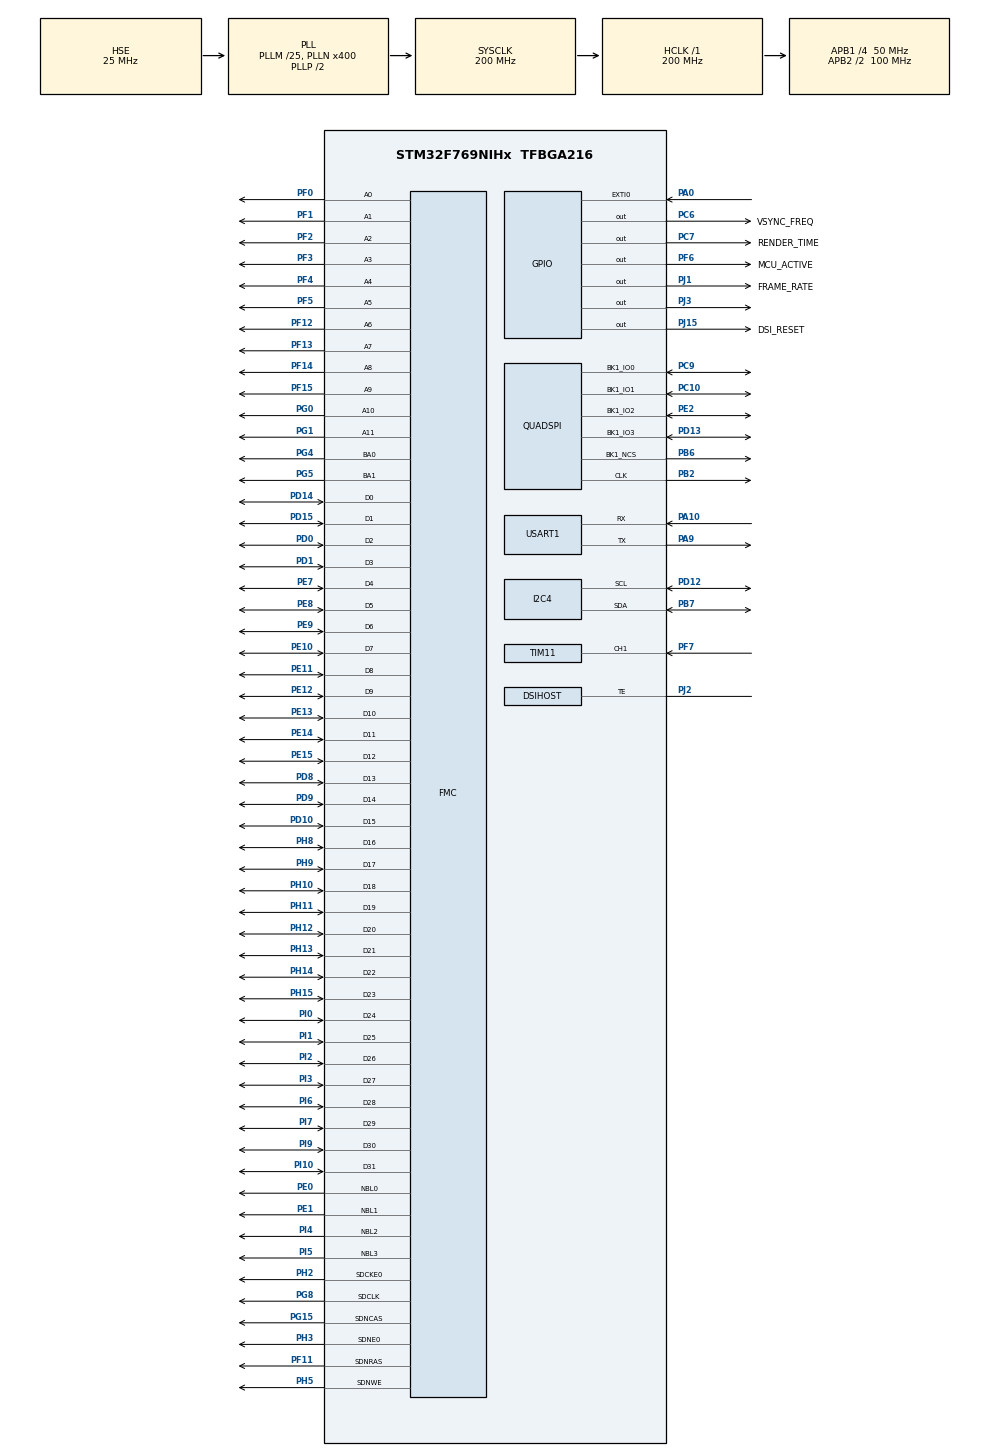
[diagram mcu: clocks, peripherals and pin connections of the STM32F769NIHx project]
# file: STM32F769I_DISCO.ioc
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CORTEX_M7.ART_ACCLERATOR_ENABLE=1
CORTEX_M7.AccessPermission-Cortex_Memory_Protection_Unit_Region0_Settings=MPU_REGION_FULL_ACCESS
CORTEX_M7.AccessPermission-Cortex_Memory_Protection_Unit_Region1_Settings=MPU_REGION_NO_ACCESS
CORTEX_M7.AccessPermission-Cortex_Memory_Protection_Unit_Region2_Settings=MPU_REGION_FULL_ACCESS
CORTEX_M7.AccessPermission-Cortex_Memory_Protection_Unit_Region3_Settings=MPU_REGION_NO_ACCESS
CORTEX_M7.AccessPermission-Cortex_Memory_Protection_Unit_Region4_Settings=MPU_REGION_FULL_ACCESS
CORTEX_M7.BaseAddress-Cortex_Memory_Protection_Unit_Region0_Settings=0x20000000
CORTEX_M7.BaseAddress-Cortex_Memory_Protection_Unit_Region1_Settings=0x90000000
CORTEX_M7.BaseAddress-Cortex_Memory_Protection_Unit_Region2_Settings=0x90000000
CORTEX_M7.BaseAddress-Cortex_Memory_Protection_Unit_Region3_Settings=0xC0000000
CORTEX_M7.BaseAddress-Cortex_Memory_Protection_Unit_Region4_Settings=0xC0000000
CORTEX_M7.CPU_DCache=Enabled
CORTEX_M7.CPU_ICache=Enabled
CORTEX_M7.DisableExec-Cortex_Memory_Protection_Unit_Region0_Settings=MPU_INSTRUCTION_ACCESS_DISABLE
CORTEX_M7.DisableExec-Cortex_Memory_Protection_Unit_Region1_Settings=MPU_INSTRUCTION_ACCESS_DISABLE
CORTEX_M7.DisableExec-Cortex_Memory_Protection_Unit_Region2_Settings=MPU_INSTRUCTION_ACCESS_DISABLE
CORTEX_M7.DisableExec-Cortex_Memory_Protection_Unit_Region3_Settings=MPU_INSTRUCTION_ACCESS_DISABLE
CORTEX_M7.DisableExec-Cortex_Memory_Protection_Unit_Region4_Settings=MPU_INSTRUCTION_ACCESS_DISABLE
CORTEX_M7.Enable-Cortex_Memory_Protection_Unit_Region0_Settings=MPU_REGION_ENABLE
CORTEX_M7.Enable-Cortex_Memory_Protection_Unit_Region1_Settings=MPU_REGION_ENABLE
CORTEX_M7.Enable-Cortex_Memory_Protection_Unit_Region2_Settings=MPU_REGION_ENABLE
CORTEX_M7.Enable-Cortex_Memory_Protection_Unit_Region3_Settings=MPU_REGION_ENABLE
CORTEX_M7.Enable-Cortex_Memory_Protection_Unit_Region4_Settings=MPU_REGION_ENABLE
CORTEX_M7.IsBufferable-Cortex_Memory_Protection_Unit_Region0_Settings=MPU_ACCESS_BUFFERABLE
CORTEX_M7.IsBufferable-Cortex_Memory_Protection_Unit_Region2_Settings=MPU_ACCESS_BUFFERABLE
CORTEX_M7.IsBufferable-Cortex_Memory_Protection_Unit_Region3_Settings=MPU_ACCESS_NOT_BUFFERABLE
CORTEX_M7.IsBufferable-Cortex_Memory_Protection_Unit_Region4_Settings=MPU_ACCESS_BUFFERABLE
CORTEX_M7.IsCacheable-Cortex_Memory_Protection_Unit_Region0_Settings=MPU_ACCESS_CACHEABLE
CORTEX_M7.IsCacheable-Cortex_Memory_Protection_Unit_Region2_Settings=MPU_ACCESS_CACHEABLE
CORTEX_M7.IsCacheable-Cortex_Memory_Protection_Unit_Region3_Settings=MPU_ACCESS_NOT_CACHEABLE
CORTEX_M7.IsCacheable-Cortex_Memory_Protection_Unit_Region4_Settings=MPU_ACCESS_CACHEABLE
CORTEX_M7.IsShareable-Cortex_Memory_Protection_Unit_Region0_Settings=MPU_ACCESS_NOT_SHAREABLE
CORTEX_M7.IsShareable-Cortex_Memory_Protection_Unit_Region2_Settings=MPU_ACCESS_NOT_SHAREABLE
CORTEX_M7.MPU_Control=MPU_PRIVILEGED_DEFAULT
CORTEX_M7.PREFETCH_ENABLE=1
CORTEX_M7.Size-Cortex_Memory_Protection_Unit_Region0_Settings=MPU_REGION_SIZE_512KB
CORTEX_M7.Size-Cortex_Memory_Protection_Unit_Region1_Settings=MPU_REGION_SIZE_512MB
CORTEX_M7.Size-Cortex_Memory_Protection_Unit_Region2_Settings=MPU_REGION_SIZE_64MB
CORTEX_M7.Size-Cortex_Memory_Protection_Unit_Region3_Settings=MPU_REGION_SIZE_512MB
CORTEX_M7.Size-Cortex_Memory_Protection_Unit_Region4_Settings=MPU_REGION_SIZE_16MB
DMA2D.ColorMode=DMA2D_OUTPUT_ARGB8888
DMA2D.Mode=DMA2D_M2M
DSIHOST.AcknowledgeRequest=DSI_ACKNOWLEDGE_ENABLE
DSIHOST.AutomaticRefresh=DSI_AR_DISABLE
DSIHOST.BTA_FlowControl=DSI_FLOW_CONTROL_BTA
DSIHOST.CommandSize=200
DSIHOST.LPDcsLongWrite=DSI_LP_DLW_ENABLE
DSIHOST.LPDcsShortReadNoP=DSI_LP_DSR0P_ENABLE
DSIHOST.LPDcsShortWriteNoP=DSI_LP_DSW0P_ENABLE
DSIHOST.LPDcsShortWriteOneP=DSI_LP_DSW1P_ENABLE
DSIHOST.LPGenLongWrite=DSI_LP_GLW_ENABLE
DSIHOST.LPGenShortReadNoP=DSI_LP_GSR0P_ENABLE
DSIHOST.LPGenShortReadOneP=DSI_LP_GSR1P_ENABLE
DSIHOST.LPGenShortReadTwoP=DSI_LP_GSR2P_ENABLE
DSIHOST.LPGenShortWriteNoP=DSI_LP_GSW0P_ENABLE
DSIHOST.LPGenShortWriteOneP=DSI_LP_GSW1P_ENABLE
DSIHOST.LPGenShortWriteTwoP=DSI_LP_GSW2P_ENABLE
DSIHOST.LPMaxReadPacket=DSI_LP_MRDP_ENABLE
DSIHOST.LPWREIE=HAL_DSI_ERROR_OVF
DSIHOST.NumberOfLanes=DSI_TWO_DATA_LANES
DSIHOST.TEAcknowledgeRequest=DSI_TE_ACKNOWLEDGE_ENABLE
DSIHOST_CKN.Mode=DSIHost_Adapted_TE
DSIHOST_CKN.Signal=DSIHOST_CKN
DSIHOST_CKP.Mode=DSIHost_Adapted_TE
DSIHOST_CKP.Signal=DSIHOST_CKP
DSIHOST_D0N.Mode=DSIHost_Adapted_TE
DSIHOST_D0N.Signal=DSIHOST_D0N
DSIHOST_D0P.Mode=DSIHost_Adapted_TE
DSIHOST_D0P.Signal=DSIHOST_D0P
DSIHOST_D1N.Mode=DSIHost_Adapted_TE
DSIHOST_D1N.Signal=DSIHOST_D1N
DSIHOST_D1P.Mode=DSIHost_Adapted_TE
DSIHOST_D1P.Signal=DSIHOST_D1P
Dma.JPEG_IN.0.Direction=DMA_MEMORY_TO_PERIPH
Dma.JPEG_IN.0.FIFOMode=DMA_FIFOMODE_ENABLE
Dma.JPEG_IN.0.FIFOThreshold=DMA_FIFO_THRESHOLD_FULL
Dma.JPEG_IN.0.Instance=DMA2_Stream0
Dma.JPEG_IN.0.MemBurst=DMA_MBURST_INC4
Dma.JPEG_IN.0.MemDataAlignment=DMA_MDATAALIGN_WORD
Dma.JPEG_IN.0.MemInc=DMA_MINC_ENABLE
Dma.JPEG_IN.0.Mode=DMA_NORMAL
Dma.JPEG_IN.0.PeriphBurst=DMA_PBURST_INC4
Dma.JPEG_IN.0.PeriphDataAlignment=DMA_PDATAALIGN_WORD
Dma.JPEG_IN.0.PeriphInc=DMA_PINC_DISABLE
Dma.JPEG_IN.0.Priority=DMA_PRIORITY_LOW
Dma.JPEG_OUT.1.Direction=DMA_PERIPH_TO_MEMORY
Dma.JPEG_OUT.1.FIFOMode=DMA_FIFOMODE_ENABLE
Dma.JPEG_OUT.1.FIFOThreshold=DMA_FIFO_THRESHOLD_FULL
Dma.JPEG_OUT.1.Instance=DMA2_Stream1
Dma.JPEG_OUT.1.MemBurst=DMA_MBURST_INC4
Dma.JPEG_OUT.1.MemDataAlignment=DMA_MDATAALIGN_WORD
Dma.JPEG_OUT.1.MemInc=DMA_MINC_ENABLE
Dma.JPEG_OUT.1.Mode=DMA_NORMAL
Dma.JPEG_OUT.1.PeriphBurst=DMA_PBURST_INC4
Dma.JPEG_OUT.1.PeriphDataAlignment=DMA_PDATAALIGN_WORD
Dma.JPEG_OUT.1.PeriphInc=DMA_PINC_DISABLE
Dma.JPEG_OUT.1.Priority=DMA_PRIORITY_LOW
Dma.Request0=JPEG_IN
Dma.Request1=JPEG_OUT
FMC.CASLatency1=FMC_SDRAM_CAS_LATENCY_3
FMC.ExitSelfRefreshDelay1=7
FMC.LoadToActiveDelay1=2
FMC.RCDDelay1=3
FMC.RPDelay1=2
FMC.ReadBurst1=FMC_SDRAM_RBURST_ENABLE
FMC.RowCycleDelay1=7
FMC.SDClockPeriod1=FMC_SDRAM_CLOCK_PERIOD_2
FMC.SelfRefreshTime1=4
FMC.WriteRecoveryTime1=2
FREERTOS.Tasks01=defaultTask,24,128,StartDefaultTask,Default,NULL,Dynamic,NULL,NULL;TouchGFXTask,24,4096,TouchGFX_Task,As external,NULL,Dynamic,NULL,NULL;videoTask,8,1000,videoTaskFunc,As external,NULL,Dynamic,NULL,NULL
FREERTOS.configTOTAL_HEAP_SIZE=80000
FREERTOS.configUSE_IDLE_HOOK=1
FREERTOS.configUSE_NEWLIB_REENTRANT=1
I2C4.Timing=0x00C0EAFF
JPEG.JPEG_RGB_FORMAT=JPEG_RGB565
LIBJPEG.RGB_ORDERING=BGR
LTDC.ActiveH=480
LTDC.ActiveW=200
LTDC.Alpha_L0=255
LTDC.BlendingFactor1_L0=LTDC_BLENDING_FACTOR1_CA
LTDC.BlendingFactor2_L0=LTDC_BLENDING_FACTOR2_CA
LTDC.FBStartAdress_L0=0xC0000000
LTDC.HBP=1
LTDC.HFP=1
LTDC.HSync=2
LTDC.ImageHeight_L0=480
LTDC.ImageWidth_L0=200
LTDC.Layers=0
LTDC.PixelFormat_L0=LTDC_PIXEL_FORMAT_RGB565
LTDC.Red=0
LTDC.VBP=1
LTDC.VFP=1
LTDC.VSync=2
LTDC.WindowX1_L0=200
LTDC.WindowY1_L0=480
Mcu.Family=STM32F7
Mcu.Name=STM32F769NIHx
Mcu.Package=TFBGA216
NVIC.DMA2D_IRQn=true\:5\:0\:false\:false\:true\:true\:true\:true\:true
NVIC.DMA2_Stream0_IRQn=true\:5\:0\:false\:false\:true\:true\:false\:true\:true
NVIC.DMA2_Stream1_IRQn=true\:5\:0\:false\:false\:true\:true\:false\:true\:true
NVIC.DSI_IRQn=true\:5\:0\:false\:false\:true\:true\:true\:true\:true
NVIC.EXTI0_IRQn=true\:5\:0\:false\:false\:true\:true\:true\:true\:true
NVIC.I2C4_EV_IRQn=true\:5\:0\:false\:false\:true\:false\:true\:true\:true
NVIC.JPEG_IRQn=true\:5\:0\:false\:false\:true\:true\:false\:true\:true
NVIC.LTDC_IRQn=true\:3\:0\:true\:false\:true\:false\:true\:true\:true
NVIC.PriorityGroup=NVIC_PRIORITYGROUP_4
NVIC.TIM1_TRG_COM_TIM11_IRQn=true\:5\:0\:false\:false\:true\:true\:true\:true\:true
NVIC.TIM6_DAC_IRQn=true\:0\:0\:false\:false\:true\:false\:false\:true\:true
NVIC.TimeBase=TIM6_DAC_IRQn
NVIC.TimeBaseIP=TIM6
NVIC.USART1_IRQn=true\:5\:0\:false\:false\:true\:true\:true\:true\:true
PA0/WKUP.Signal=GPXTI0
PA10.Mode=Asynchronous
PA10.Signal=USART1_RX
PA9.Mode=Asynchronous
PA9.Signal=USART1_TX
PB2.Mode=Single Bank 1
PB2.Signal=QUADSPI_CLK
PB6.GPIO_PuPd=GPIO_PULLUP
PB6.Mode=Single Bank 1
PB6.Signal=QUADSPI_BK1_NCS
PB7.GPIO_Pu=GPIO_PULLUP
PB7.Mode=I2C
PB7.Signal=I2C4_SDA
PC10.Mode=Single Bank 1
PC10.Signal=QUADSPI_BK1_IO1
PC6.GPIO_Label=VSYNC_FREQ
PC6.GPIO_Speed=GPIO_SPEED_FREQ_VERY_HIGH
PC6.Signal=GPIO_Output
PC7.GPIO_Label=RENDER_TIME
PC7.GPIO_Speed=GPIO_SPEED_FREQ_VERY_HIGH
PC7.Signal=GPIO_Output
PC9.Mode=Single Bank 1
PC9.Signal=QUADSPI_BK1_IO0
PD0.Signal=FMC_D2_DA2
PD1.Signal=FMC_D3_DA3
PD10.Signal=FMC_D15_DA15
PD12.GPIO_Pu=GPIO_PULLUP
PD12.Mode=I2C
PD12.Signal=I2C4_SCL
PD13.Mode=Single Bank 1
PD13.Signal=QUADSPI_BK1_IO3
PD14.Signal=FMC_D0_DA0
PD15.Signal=FMC_D1_DA1
PD8.Signal=FMC_D13_DA13
PD9.Signal=FMC_D14_DA14
PE0.Signal=FMC_NBL0
PE1.Signal=FMC_NBL1
PE10.Signal=FMC_D7_DA7
PE11.Signal=FMC_D8_DA8
PE12.Signal=FMC_D9_DA9
PE13.Signal=FMC_D10_DA10
PE14.Signal=FMC_D11_DA11
PE15.Signal=FMC_D12_DA12
PE2.Mode=Single Bank 1
PE2.Signal=QUADSPI_BK1_IO2
PE7.Signal=FMC_D4_DA4
PE8.Signal=FMC_D5_DA5
PE9.Signal=FMC_D6_DA6
PF0.Signal=FMC_A0
PF1.Signal=FMC_A1
PF11.Signal=FMC_SDNRAS
PF12.Signal=FMC_A6
PF13.Signal=FMC_A7
PF14.Signal=FMC_A8
PF15.Signal=FMC_A9
PF2.Signal=FMC_A2
PF3.Signal=FMC_A3
PF4.Signal=FMC_A4
PF5.Signal=FMC_A5
PF6.GPIO_Label=MCU_ACTIVE
PF6.GPIO_Speed=GPIO_SPEED_FREQ_VERY_HIGH
PF6.Signal=GPIO_Output
PF7.Signal=S_TIM11_CH1
PG0.Signal=FMC_A10
PG1.Signal=FMC_A11
PG15.Signal=FMC_SDNCAS
PG4.Signal=FMC_A14_BA0
PG5.Signal=FMC_A15_BA1
PG8.Signal=FMC_SDCLK
PH0/OSC_IN.Mode=HSE-External-Oscillator
PH0/OSC_IN.Signal=RCC_OSC_IN
PH1/OSC_OUT.Mode=HSE-External-Oscillator
PH1/OSC_OUT.Signal=RCC_OSC_OUT
PH10.Signal=FMC_D18
PH11.Signal=FMC_D19
PH12.Signal=FMC_D20
PH13.Signal=FMC_D21
PH14.Signal=FMC_D22
PH15.Signal=FMC_D23
PH2.Mode=SdramChipSelect1_1
PH2.Signal=FMC_SDCKE0
PH3.Mode=SdramChipSelect1_1
PH3.Signal=FMC_SDNE0
PH5.Signal=FMC_SDNWE
PH8.Signal=FMC_D16
PH9.Signal=FMC_D17
PI0.Signal=FMC_D24
PI1.Signal=FMC_D25
PI10.Signal=FMC_D31
PI2.Signal=FMC_D26
PI3.Signal=FMC_D27
PI4.Signal=FMC_NBL2
PI5.Signal=FMC_NBL3
PI6.Signal=FMC_D28
PI7.Signal=FMC_D29
PI9.Signal=FMC_D30
PJ1.GPIO_Label=FRAME_RATE
PJ1.GPIO_Speed=GPIO_SPEED_FREQ_VERY_HIGH
PJ1.Signal=GPIO_Output
PJ15.GPIO_Label=DSI_RESET
PJ15.GPIO_PuPd=GPIO_PULLUP
PJ15.GPIO_Speed=GPIO_SPEED_FREQ_MEDIUM
PJ15.PinState=GPIO_PIN_SET
PJ15.Signal=GPIO_Output
PJ2.Mode=DSIHost_Adapted_TE
PJ2.Signal=DSIHOST_TE
PJ3.Signal=GPIO_Output
ProjectManager.HeapSize=0x1000
ProjectManager.StackSize=0x1000
ProjectManager.TargetToolchain=STM32CubeIDE
QUADSPI.ChipSelectHighTime=QSPI_CS_HIGH_TIME_4_CYCLE
QUADSPI.ClockPrescaler=1
QUADSPI.FifoThreshold=16
QUADSPI.FlashSize=25
QUADSPI.SampleShifting=QSPI_SAMPLE_SHIFTING_HALFCYCLE
RCC.AHBFreq_Value=200000000
RCC.APB1CLKDivider=RCC_HCLK_DIV4
RCC.APB1Freq_Value=50000000
RCC.APB1TimFreq_Value=100000000
RCC.APB2CLKDivider=RCC_HCLK_DIV2
RCC.APB2Freq_Value=100000000
RCC.APB2TimFreq_Value=200000000
RCC.CortexFreq_Value=200000000
RCC.HCLKFreq_Value=200000000
RCC.HSE_VALUE=25000000
RCC.HSI_VALUE=16000000
RCC.LSE_VALUE=32768
RCC.PLLDSIIDF=DSI_PLL_IN_DIV5
RCC.PLLDSINDIV=100
RCC.PLLM=25
RCC.PLLN=400
RCC.PLLR=7
RCC.PLLSAIN=384
RCC.PLLSAIR=7
RCC.PLLSourceVirtual=RCC_PLLSOURCE_HSE
RCC.SYSCLKFreq_VALUE=200000000
RCC.SYSCLKSource=RCC_SYSCLKSOURCE_PLLCLK
RCC.USBFreq_Value=200000000
RCC.VCOOutputFreq_Value=400000000
SH.FMC_A0.0=FMC_A0,12b-sda1
SH.FMC_A1.0=FMC_A1,12b-sda1
SH.FMC_A10.0=FMC_A10,12b-sda1
SH.FMC_A11.0=FMC_A11,12b-sda1
SH.FMC_A14_BA0.0=FMC_BA0,FourSdramBanks1
SH.FMC_A15_BA1.0=FMC_BA1,FourSdramBanks1
SH.FMC_A2.0=FMC_A2,12b-sda1
SH.FMC_A3.0=FMC_A3,12b-sda1
SH.FMC_A4.0=FMC_A4,12b-sda1
SH.FMC_A5.0=FMC_A5,12b-sda1
SH.FMC_A6.0=FMC_A6,12b-sda1
SH.FMC_A7.0=FMC_A7,12b-sda1
SH.FMC_A8.0=FMC_A8,12b-sda1
SH.FMC_A9.0=FMC_A9,12b-sda1
SH.FMC_D0_DA0.0=FMC_D0,sd-32b-d1
SH.FMC_D10_DA10.0=FMC_D10,sd-32b-d1
SH.FMC_D11_DA11.0=FMC_D11,sd-32b-d1
SH.FMC_D12_DA12.0=FMC_D12,sd-32b-d1
SH.FMC_D13_DA13.0=FMC_D13,sd-32b-d1
SH.FMC_D14_DA14.0=FMC_D14,sd-32b-d1
SH.FMC_D15_DA15.0=FMC_D15,sd-32b-d1
SH.FMC_D16.0=FMC_D16,sd-32b-d1
SH.FMC_D17.0=FMC_D17,sd-32b-d1
SH.FMC_D18.0=FMC_D18,sd-32b-d1
SH.FMC_D19.0=FMC_D19,sd-32b-d1
SH.FMC_D1_DA1.0=FMC_D1,sd-32b-d1
SH.FMC_D20.0=FMC_D20,sd-32b-d1
SH.FMC_D21.0=FMC_D21,sd-32b-d1
SH.FMC_D22.0=FMC_D22,sd-32b-d1
SH.FMC_D23.0=FMC_D23,sd-32b-d1
SH.FMC_D24.0=FMC_D24,sd-32b-d1
SH.FMC_D25.0=FMC_D25,sd-32b-d1
SH.FMC_D26.0=FMC_D26,sd-32b-d1
SH.FMC_D27.0=FMC_D27,sd-32b-d1
SH.FMC_D28.0=FMC_D28,sd-32b-d1
SH.FMC_D29.0=FMC_D29,sd-32b-d1
SH.FMC_D2_DA2.0=FMC_D2,sd-32b-d1
SH.FMC_D30.0=FMC_D30,sd-32b-d1
SH.FMC_D31.0=FMC_D31,sd-32b-d1
SH.FMC_D3_DA3.0=FMC_D3,sd-32b-d1
SH.FMC_D4_DA4.0=FMC_D4,sd-32b-d1
SH.FMC_D5_DA5.0=FMC_D5,sd-32b-d1
SH.FMC_D6_DA6.0=FMC_D6,sd-32b-d1
SH.FMC_D7_DA7.0=FMC_D7,sd-32b-d1
SH.FMC_D8_DA8.0=FMC_D8,sd-32b-d1
SH.FMC_D9_DA9.0=FMC_D9,sd-32b-d1
SH.FMC_NBL0.0=FMC_NBL0,Sd4ByteEnable1
SH.FMC_NBL1.0=FMC_NBL1,Sd4ByteEnable1
SH.FMC_NBL2.0=FMC_NBL2,Sd4ByteEnable1
SH.FMC_NBL3.0=FMC_NBL3,Sd4ByteEnable1
SH.FMC_SDCLK.0=FMC_SDCLK,12b-sda1
SH.FMC_SDNCAS.0=FMC_SDNCAS,12b-sda1
SH.FMC_SDNRAS.0=FMC_SDNRAS,12b-sda1
SH.FMC_SDNWE.0=FMC_SDNWE,12b-sda1
SH.S_TIM11_CH1.0=TIM11_CH1,Input_Capture1_from_TI1
STMicroelectronics.X-CUBE-TOUCHGFX.4.22.1.ApplicationCcGraphicsJjApplication=TouchGFXOoGenerator
STMicroelectronics.X-CUBE-TOUCHGFX.4.22.1.tgfx_address1=0xC0000000
STMicroelectronics.X-CUBE-TOUCHGFX.4.22.1.tgfx_address2=0xC011A000
STMicroelectronics.X-CUBE-TOUCHGFX.4.22.1.tgfx_buffering_strategy=Single
STMicroelectronics.X-CUBE-TOUCHGFX.4.22.1.tgfx_custom_height=480
STMicroelectronics.X-CUBE-TOUCHGFX.4.22.1.tgfx_custom_width=800
STMicroelectronics.X-CUBE-TOUCHGFX.4.22.1.tgfx_hardware_accelerator=dma_2d
STMicroelectronics.X-CUBE-TOUCHGFX.4.22.1.tgfx_location=Allocate
STMicroelectronics.X-CUBE-TOUCHGFX.4.22.1.tgfx_pixel_format=RGB565\:16
STMicroelectronics.X-CUBE-TOUCHGFX.4.22.1.tgfx_vector_rendering=Enabled
STMicroelectronics.X-CUBE-TOUCHGFX.4.22.1.tgfx_video=Hardware
STMicroelectronics.X-CUBE-TOUCHGFX.4.22.1.tgfx_video_height=480
STMicroelectronics.X-CUBE-TOUCHGFX.4.22.1.tgfx_video_strategy=1
STMicroelectronics.X-CUBE-TOUCHGFX.4.22.1.tgfx_video_width=800
TIM11.Channel=TIM_CHANNEL_1
TIM11.Period=0xffff-1
TIM11.Prescaler=95
USART1.VirtualMode-Asynchronous=VM_ASYNC
VP_CRC_VS_CRC.Mode=CRC_Activate
VP_DMA2D_VS_DMA2D.Mode=DMA2D_Activate
VP_FREERTOS_VS_CMSIS_V2.Mode=CMSIS_V2
VP_JPEG_VS_JPEG.Mode=JPEG_Activate
VP_LIBJPEG_VS_JPEGLIB.Mode=Enabled
VP_LTDC_DSIMode.Mode=RGB565
VP_STMicroelectronics.X-CUBE-TOUCHGFX_VS_GraphicsJjApplication_4.22.1.Mode=GraphicsJjApplication
VP_SYS_VS_tim6.Mode=TIM6
VP_TIM11_VS_ClockSourceINT.Mode=Enable_Timer
board=custom

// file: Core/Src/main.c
/* USER CODE BEGIN Header */
/**
  ******************************************************************************
  * @file           : main.c
  * @brief          : Main program body
  ******************************************************************************
  * @attention
  *
  * <h2><center>&copy; Copyright (c) 2020 STMicroelectronics.
  * All rights reserved.</center></h2>
  *
  * This software component is licensed by ST under BSD 3-Clause license,
  * the "License"; You may not use this file except in compliance with the
  * License. You may obtain a copy of the License at:
  *                        opensource.org/licenses/BSD-3-Clause
  *
  ******************************************************************************
  */
/* USER CODE END Header */
#include "main.h"
#include "cmsis_os.h"
#include "libjpeg.h"
#include "app_touchgfx.h"
/* USER CODE BEGIN Includes */
#include "../mx25l512/mx25l512.h"
#include "../otm8009a/otm8009a.h"
/* USER CODE END Includes */

/* USER CODE BEGIN PD */

#define REFRESH_COUNT        1834
#define SDRAM_TIMEOUT                            ((uint32_t)0xFFFF)
#define SDRAM_MODEREG_BURST_LENGTH_1             ((uint16_t)0x0000)
#define SDRAM_MODEREG_BURST_LENGTH_2             ((uint16_t)0x0001)
#define SDRAM_MODEREG_BURST_LENGTH_4             ((uint16_t)0x0002)
#define SDRAM_MODEREG_BURST_LENGTH_8             ((uint16_t)0x0004)
#define SDRAM_MODEREG_BURST_TYPE_SEQUENTIAL      ((uint16_t)0x0000)
#define SDRAM_MODEREG_BURST_TYPE_INTERLEAVED     ((uint16_t)0x0008)
#define SDRAM_MODEREG_CAS_LATENCY_2              ((uint16_t)0x0020)
#define SDRAM_MODEREG_CAS_LATENCY_3              ((uint16_t)0x0030)
#define SDRAM_MODEREG_OPERATING_MODE_STANDARD    ((uint16_t)0x0000)
#define SDRAM_MODEREG_WRITEBURST_MODE_PROGRAMMED ((uint16_t)0x0000)
#define SDRAM_MODEREG_WRITEBURST_MODE_SINGLE     ((uint16_t)0x0200)

/* QSPI Error codes */
#define QSPI_OK            ((uint8_t)0x00)
#define QSPI_ERROR         ((uint8_t)0x01)
#define QSPI_BUSY          ((uint8_t)0x02)
#define QSPI_NOT_SUPPORTED ((uint8_t)0x04)
#define QSPI_SUSPENDED     ((uint8_t)0x08)

/* DISPLAY */
#define LCD_ORIENTATION_LANDSCAPE 0x01
/* USER CODE END PD */

CRC_HandleTypeDef hcrc;

DMA2D_HandleTypeDef hdma2d;

DSI_HandleTypeDef hdsi;

I2C_HandleTypeDef hi2c4;

JPEG_HandleTypeDef hjpeg;
DMA_HandleTypeDef hdma_jpeg_in;
DMA_HandleTypeDef hdma_jpeg_out;

LTDC_HandleTypeDef hltdc;

QSPI_HandleTypeDef hqspi;

TIM_HandleTypeDef htim11;

UART_HandleTypeDef huart1;

SDRAM_HandleTypeDef hsdram1;

/* Definitions for defaultTask */
osThreadId_t defaultTaskHandle;
const osThreadAttr_t defaultTask_attributes = {
  .name = "defaultTask",
  .stack_size = 128 * 4,
  .priority = (osPriority_t) osPriorityNormal,
};
/* Definitions for TouchGFXTask */
osThreadId_t TouchGFXTaskHandle;
const osThreadAttr_t TouchGFXTask_attributes = {
  .name = "TouchGFXTask",
  .stack_size = 4096 * 4,
  .priority = (osPriority_t) osPriorityNormal,
};
/* Definitions for videoTask */
osThreadId_t videoTaskHandle;
const osThreadAttr_t videoTask_attributes = {
  .name = "videoTask",
  .stack_size = 1000 * 4,
  .priority = (osPriority_t) osPriorityLow,
};

/* Definitions for defaultTask */
osThreadId_t sensorTaskHandle;
const osThreadAttr_t sensorTask_attributes = {
  .name = "sensorTask",
  .stack_size = 128 * 4,
  .priority = (osPriority_t) osPriorityNormal,
};
/* USER CODE BEGIN PV */
uint32_t IC_Val1 = 0;
uint32_t IC_Val2 = 0;
uint32_t Difference = 0;
uint8_t Is_First_Captured = 0;  // is the first value captured ?
uint8_t Distance  = 0;
uint8_t updateScreen = 0;
uint8_t serialNumber=0;
uint8_t distance[5]={0,0,0,0,0};

#define DHT22_PORT GPIOJ
#define DHT22_PIN  GPIO_PIN_1
uint8_t RH1, RH2, TC1, TC2, SUM, CHECK;
uint32_t pMillis, cMillis;
float tCelsius = 50;
float tFahrenheit = 0;
float RH = 0;
int a=5;

#define TRIG_PIN GPIO_PIN_3
#define TRIG_PORT GPIOJ
//#define TRIG_PIN_2 GPIO_PIN_1
/* USER CODE END PV */

void SystemClock_Config(void);
static void MPU_Initialize(void);
static void MPU_Config(void);
static void MX_GPIO_Init(void);
static void MX_DMA_Init(void);
static void MX_DSIHOST_DSI_Init(void);
static void MX_LTDC_Init(void);
static void MX_FMC_Init(void);
static void MX_QUADSPI_Init(void);
static void MX_DMA2D_Init(void);
static void MX_CRC_Init(void);
static void MX_JPEG_Init(void);
static void MX_TIM11_Init(void);
static void MX_USART1_UART_Init(void);
void StartDefaultTask(void *argument);
void sensorTaskFunc(void *argument);
extern void TouchGFX_Task(void *argument);
extern void videoTaskFunc(void *argument);

/* USER CODE BEGIN PFP */
static void BSP_SDRAM_Initialization_Sequence(SDRAM_HandleTypeDef *hsdram, FMC_SDRAM_CommandTypeDef *Command);

static uint8_t QSPI_ResetMemory(QSPI_HandleTypeDef *hqspi);
static uint8_t QSPI_EnterMemory_QPI(QSPI_HandleTypeDef *hqspi);
static uint8_t QSPI_EnterFourBytesAddress(QSPI_HandleTypeDef *hqspi);
static uint8_t QSPI_DummyCyclesCfg(QSPI_HandleTypeDef *hqspi);
static uint8_t QSPI_OutDrvStrengthCfg(QSPI_HandleTypeDef *hqspi);
static uint8_t QSPI_WriteEnable(QSPI_HandleTypeDef *hqspi);
static uint8_t QSPI_AutoPollingMemReady  (QSPI_HandleTypeDef *hqspi, uint32_t Timeout);
static uint8_t BSP_QSPI_EnableMemoryMappedMode(QSPI_HandleTypeDef *hqspi);
/* USER CODE END PFP */

/* USER CODE BEGIN 0 */
void delay (uint16_t time)
{
	__HAL_TIM_SET_COUNTER(&htim11, 0);
	while (__HAL_TIM_GET_COUNTER (&htim11) < time);
}

void HAL_TIM_IC_CaptureCallback(TIM_HandleTypeDef *htim)
{
	if (htim->Channel == HAL_TIM_ACTIVE_CHANNEL_1)  // if the interrupt source is channel1
	{
		if (Is_First_Captured==0) // if the first value is not captured
		{
			IC_Val1 = HAL_TIM_ReadCapturedValue(htim, TIM_CHANNEL_1); // read the first value
			Is_First_Captured = 1;  // set the first captured as true
			// Now change the polarity to falling edge
			__HAL_TIM_SET_CAPTUREPOLARITY(htim, TIM_CHANNEL_1, TIM_INPUTCHANNELPOLARITY_FALLING);
		}

		else if (Is_First_Captured==1)   // if the first is already captured
		{
			IC_Val2 = HAL_TIM_ReadCapturedValue(htim, TIM_CHANNEL_1);  // read second value
			__HAL_TIM_SET_COUNTER(htim, 0);  // reset the counter

			if (IC_Val2 > IC_Val1)
			{
				Difference = IC_Val2-IC_Val1;
			}

			else if (IC_Val1 > IC_Val2)
			{
				Difference = (0xffff - IC_Val1) + IC_Val2;
			}

			Distance = Difference * .034/2;
			Is_First_Captured = 0; // set it back to false

			// set polarity to rising edge
			__HAL_TIM_SET_CAPTUREPOLARITY(htim, TIM_CHANNEL_1, TIM_INPUTCHANNELPOLARITY_RISING);
			__HAL_TIM_DISABLE_IT(&htim11, TIM_IT_CC1);
		}
	}
}

uint8_t DHT22_Start (void)
{
  uint8_t Response = 0;
  GPIO_InitTypeDef GPIO_InitStructPrivate = {0};
  GPIO_InitStructPrivate.Pin = DHT22_PIN;
  GPIO_InitStructPrivate.Mode = GPIO_MODE_OUTPUT_PP;
  GPIO_InitStructPrivate.Speed = GPIO_SPEED_FREQ_LOW;
  GPIO_InitStructPrivate.Pull = GPIO_NOPULL;
  HAL_GPIO_Init(DHT22_PORT, &GPIO_InitStructPrivate); // set the pin as output
  HAL_GPIO_WritePin (DHT22_PORT, DHT22_PIN, 0);   // pull the pin low
  delay(1300);// wait for 1300us
  HAL_GPIO_WritePin (DHT22_PORT, DHT22_PIN, 1);   // pull the pin high
  delay (40);   // wait for 30us
  GPIO_InitStructPrivate.Mode = GPIO_MODE_INPUT;
  GPIO_InitStructPrivate.Pull = GPIO_PULLUP;
  HAL_GPIO_Init(DHT22_PORT, &GPIO_InitStructPrivate); // set the pin as input
  delay (40);
  if (!(HAL_GPIO_ReadPin (DHT22_PORT, DHT22_PIN)))
  {
	  delay (80);
    if ((HAL_GPIO_ReadPin (DHT22_PORT, DHT22_PIN))) Response = 1;
  }
  pMillis = HAL_GetTick();
  cMillis = HAL_GetTick();
  while ((HAL_GPIO_ReadPin (DHT22_PORT, DHT22_PIN)) && pMillis + 2 > cMillis)
  {
    cMillis = HAL_GetTick();
  }
  return Response;
}

uint8_t DHT22_Read (void)
{
  uint8_t a,b;
  for (a=0;a<8;a++)
  {
    pMillis = HAL_GetTick();
    cMillis = HAL_GetTick();
    while (!(HAL_GPIO_ReadPin (DHT22_PORT, DHT22_PIN)) && pMillis + 2 > cMillis)
    {  // wait for the pin to go high
      cMillis = HAL_GetTick();
    }
    delay (40);   // wait for 40 us
    if (!(HAL_GPIO_ReadPin (DHT22_PORT, DHT22_PIN)))   // if the pin is low
      b&= ~(1<<(7-a));
    else
      b|= (1<<(7-a));
    pMillis = HAL_GetTick();
    cMillis = HAL_GetTick();
    while ((HAL_GPIO_ReadPin (DHT22_PORT, DHT22_PIN)) && pMillis + 2 > cMillis)
    {  // wait for the pin to go low
      cMillis = HAL_GetTick();
    }
  }
  return b;
}

void DHT22_Loop(void)
{
//	HAL_GPIO_TogglePin(TRIG_PORT, TRIG_PIN_2);
//	  microDelay(50000);//10------->1us and 130000-------->13000
//  HAL_Delay(300);
//	delay(12500);
	a = DHT22_Start();
		  if(a)
			  {
				RH1 = DHT22_Read(); // First 8bits of humidity
				RH2 = DHT22_Read(); // Second 8bits of Relative humidity
				TC1 = DHT22_Read(); // First 8bits of Celsius
				TC2 = DHT22_Read(); // Second 8bits of Celsius
				SUM = DHT22_Read(); // Check sum
				CHECK = RH1 + RH2 + TC1 + TC2;
				if (CHECK == SUM)
				{
				  if (TC1>127) // If TC1=10000000, negative temperature
				  {
					tCelsius = (float)TC2/10*(-1);
				  }
				  else
				  {
					tCelsius = (float)((TC1<<8)|TC2)/10;
				  }
				  tFahrenheit = tCelsius * 9/5 + 32;
				  RH = (float) ((RH1<<8)|RH2)/10;
				}
			  }
		  Distance = tCelsius;
	__HAL_TIM_ENABLE_IT(&htim11, TIM_IT_CC1);
}

void HCSR04_Read()
{
	HAL_GPIO_WritePin(TRIG_PORT, TRIG_PIN, GPIO_PIN_SET);  // pull the TRIG pin HIGH
	HAL_Delay(10);  // wait for 10 us
	HAL_GPIO_WritePin(TRIG_PORT, TRIG_PIN, GPIO_PIN_RESET);  // pull the TRIG pin low
	__HAL_TIM_ENABLE_IT(&htim11, TIM_IT_CC1);
}
/* USER CODE END 0 */

int main(void)
{

  /* Enable I-Cache---------------------------------------------------------*/
  SCB_EnableICache();

  /* Enable D-Cache---------------------------------------------------------*/
  SCB_EnableDCache();

  /* MCU Configuration--------------------------------------------------------*/

  /* Reset of all peripherals, Initializes the Flash interface and the Systick. */
  HAL_Init();

  /* MPU Configuration--------------------------------------------------------*/
  MPU_Config();

  /* Configure the system clock */
  SystemClock_Config();

  /* Initialize all configured peripherals */
  MX_GPIO_Init();
  MX_DMA_Init();
  MX_DSIHOST_DSI_Init();
  MX_LTDC_Init();
  MX_FMC_Init();
  MX_QUADSPI_Init();
  MX_DMA2D_Init();
  MX_I2C4_Init();
  MX_LIBJPEG_Init();
  MX_CRC_Init();
  MX_JPEG_Init();
  MX_TIM11_Init();
  MX_USART1_UART_Init();
  MX_TouchGFX_Init();
  /* Call PreOsInit function */
  MX_TouchGFX_PreOSInit();
  /* USER CODE BEGIN 2 */
  HAL_TIM_IC_Start_IT(&htim11, TIM_CHANNEL_1);

  /* USER CODE END 2 */

  /* Init scheduler */
  osKernelInitialize();

  /* Create the thread(s) */
  /* creation of defaultTask */
  defaultTaskHandle = osThreadNew(StartDefaultTask, NULL, &defaultTask_attributes);

  /* creation of TouchGFXTask */
  TouchGFXTaskHandle = osThreadNew(TouchGFX_Task, NULL, &TouchGFXTask_attributes);

  /* creation of videoTask */
  videoTaskHandle = osThreadNew(videoTaskFunc, NULL, &videoTask_attributes);

  /* creation of sensorTask */
    sensorTaskHandle = osThreadNew(sensorTaskFunc, NULL, &sensorTask_attributes);

  /* Start scheduler */
  osKernelStart();

  /* We should never get here as control is now taken by the scheduler */
  /* Infinite loop */
  while (1)
  {

  }
}

void SystemClock_Config(void)
{
  RCC_OscInitTypeDef RCC_OscInitStruct = {0};
  RCC_ClkInitTypeDef RCC_ClkInitStruct = {0};

  /** Configure the main internal regulator output voltage
  */
  __HAL_RCC_PWR_CLK_ENABLE();
  __HAL_PWR_VOLTAGESCALING_CONFIG(PWR_REGULATOR_VOLTAGE_SCALE1);

  /** Initializes the RCC Oscillators according to the specified parameters
  * in the RCC_OscInitTypeDef structure.
  */
  RCC_OscInitStruct.OscillatorType = RCC_OSCILLATORTYPE_HSI|RCC_OSCILLATORTYPE_HSE;
  RCC_OscInitStruct.HSEState = RCC_HSE_ON;
  RCC_OscInitStruct.HSIState = RCC_HSI_ON;
  RCC_OscInitStruct.HSICalibrationValue = RCC_HSICALIBRATION_DEFAULT;
  RCC_OscInitStruct.PLL.PLLState = RCC_PLL_ON;
  RCC_OscInitStruct.PLL.PLLSource = RCC_PLLSOURCE_HSE;
  RCC_OscInitStruct.PLL.PLLM = 25;
  RCC_OscInitStruct.PLL.PLLN = 400;
  RCC_OscInitStruct.PLL.PLLP = RCC_PLLP_DIV2;
  RCC_OscInitStruct.PLL.PLLQ = 2;
  RCC_OscInitStruct.PLL.PLLR = 7;
  if (HAL_RCC_OscConfig(&RCC_OscInitStruct) != HAL_OK)
  {
    Error_Handler();
  }

  /** Activate the Over-Drive mode
  */
  if (HAL_PWREx_EnableOverDrive() != HAL_OK)
  {
    Error_Handler();
  }

  /** Initializes the CPU, AHB and APB buses clocks
  */
  RCC_ClkInitStruct.ClockType = RCC_CLOCKTYPE_HCLK|RCC_CLOCKTYPE_SYSCLK
                              |RCC_CLOCKTYPE_PCLK1|RCC_CLOCKTYPE_PCLK2;
  RCC_ClkInitStruct.SYSCLKSource = RCC_SYSCLKSOURCE_PLLCLK;
  RCC_ClkInitStruct.AHBCLKDivider = RCC_SYSCLK_DIV1;
  RCC_ClkInitStruct.APB1CLKDivider = RCC_HCLK_DIV4;
  RCC_ClkInitStruct.APB2CLKDivider = RCC_HCLK_DIV2;

  if (HAL_RCC_ClockConfig(&RCC_ClkInitStruct, FLASH_LATENCY_6) != HAL_OK)
  {
    Error_Handler();
  }
  HAL_RCC_MCOConfig(RCC_MCO1, RCC_MCO1SOURCE_HSI, RCC_MCODIV_1);
}

static void MX_CRC_Init(void)
{

  hcrc.Instance = CRC;
  hcrc.Init.DefaultPolynomialUse = DEFAULT_POLYNOMIAL_ENABLE;
  hcrc.Init.DefaultInitValueUse = DEFAULT_INIT_VALUE_ENABLE;
  hcrc.Init.InputDataInversionMode = CRC_INPUTDATA_INVERSION_NONE;
  hcrc.Init.OutputDataInversionMode = CRC_OUTPUTDATA_INVERSION_DISABLE;
  hcrc.InputDataFormat = CRC_INPUTDATA_FORMAT_BYTES;
  if (HAL_CRC_Init(&hcrc) != HAL_OK)
  {
    Error_Handler();
  }

}

static void MX_DMA2D_Init(void)
{

  hdma2d.Instance = DMA2D;
  hdma2d.Init.Mode = DMA2D_M2M;
  hdma2d.Init.ColorMode = DMA2D_OUTPUT_ARGB8888;
  hdma2d.Init.OutputOffset = 0;
  hdma2d.LayerCfg[1].InputOffset = 0;
  hdma2d.LayerCfg[1].InputColorMode = DMA2D_INPUT_ARGB8888;
  hdma2d.LayerCfg[1].AlphaMode = DMA2D_NO_MODIF_ALPHA;
  hdma2d.LayerCfg[1].InputAlpha = 0;
  hdma2d.LayerCfg[1].AlphaInverted = DMA2D_REGULAR_ALPHA;
  hdma2d.LayerCfg[1].RedBlueSwap = DMA2D_RB_REGULAR;
  if (HAL_DMA2D_Init(&hdma2d) != HAL_OK)
  {
    Error_Handler();
  }
  if (HAL_DMA2D_ConfigLayer(&hdma2d, 1) != HAL_OK)
  {
    Error_Handler();
  }

}

static void MX_DSIHOST_DSI_Init(void)
{

  /* USER CODE BEGIN DSIHOST_Init 0 */
  /* Activate XRES active low */
  HAL_GPIO_WritePin(DSI_RESET_GPIO_Port, DSI_RESET_Pin, GPIO_PIN_RESET);
  HAL_Delay(20); /* wait 20 ms */
  /* Desactivate XRES */
  HAL_GPIO_WritePin(DSI_RESET_GPIO_Port, DSI_RESET_Pin, GPIO_PIN_SET);
  /* Wait for 10ms after releasing XRES before sending commands */
  HAL_Delay(10);
  /* USER CODE END DSIHOST_Init 0 */

  DSI_PLLInitTypeDef PLLInit = {0};
  DSI_HOST_TimeoutTypeDef HostTimeouts = {0};
  DSI_PHY_TimerTypeDef PhyTimings = {0};
  DSI_LPCmdTypeDef LPCmd = {0};
  DSI_CmdCfgTypeDef CmdCfg = {0};

  hdsi.Instance = DSI;
  hdsi.Init.AutomaticClockLaneControl = DSI_AUTO_CLK_LANE_CTRL_DISABLE;
  hdsi.Init.TXEscapeCkdiv = 4;
  hdsi.Init.NumberOfLanes = DSI_TWO_DATA_LANES;
  PLLInit.PLLNDIV = 100;
  PLLInit.PLLIDF = DSI_PLL_IN_DIV5;
  PLLInit.PLLODF = DSI_PLL_OUT_DIV1;
  if (HAL_DSI_Init(&hdsi, &PLLInit) != HAL_OK)
  {
    Error_Handler();
  }
  HostTimeouts.TimeoutCkdiv = 1;
  HostTimeouts.HighSpeedTransmissionTimeout = 0;
  HostTimeouts.LowPowerReceptionTimeout = 0;
  HostTimeouts.HighSpeedReadTimeout = 0;
  HostTimeouts.LowPowerReadTimeout = 0;
  HostTimeouts.HighSpeedWriteTimeout = 0;
  HostTimeouts.HighSpeedWritePrespMode = DSI_HS_PM_DISABLE;
  HostTimeouts.LowPowerWriteTimeout = 0;
  HostTimeouts.BTATimeout = 0;
  if (HAL_DSI_ConfigHostTimeouts(&hdsi, &HostTimeouts) != HAL_OK)
  {
    Error_Handler();
  }
  PhyTimings.ClockLaneHS2LPTime = 28;
  PhyTimings.ClockLaneLP2HSTime = 33;
  PhyTimings.DataLaneHS2LPTime = 15;
  PhyTimings.DataLaneLP2HSTime = 25;
  PhyTimings.DataLaneMaxReadTime = 0;
  PhyTimings.StopWaitTime = 0;
  if (HAL_DSI_ConfigPhyTimer(&hdsi, &PhyTimings) != HAL_OK)
  {
    Error_Handler();
  }
  if (HAL_DSI_ConfigFlowControl(&hdsi, DSI_FLOW_CONTROL_BTA) != HAL_OK)
  {
    Error_Handler();
  }
  if (HAL_DSI_SetLowPowerRXFilter(&hdsi, 10000) != HAL_OK)
  {
    Error_Handler();
  }
  if (HAL_DSI_ConfigErrorMonitor(&hdsi, HAL_DSI_ERROR_OVF) != HAL_OK)
  {
    Error_Handler();
  }
  LPCmd.LPGenShortWriteNoP = DSI_LP_GSW0P_ENABLE;
  LPCmd.LPGenShortWriteOneP = DSI_LP_GSW1P_ENABLE;
  LPCmd.LPGenShortWriteTwoP = DSI_LP_GSW2P_ENABLE;
  LPCmd.LPGenShortReadNoP = DSI_LP_GSR0P_ENABLE;
  LPCmd.LPGenShortReadOneP = DSI_LP_GSR1P_ENABLE;
  LPCmd.LPGenShortReadTwoP = DSI_LP_GSR2P_ENABLE;
  LPCmd.LPGenLongWrite = DSI_LP_GLW_ENABLE;
  LPCmd.LPDcsShortWriteNoP = DSI_LP_DSW0P_ENABLE;
  LPCmd.LPDcsShortWriteOneP = DSI_LP_DSW1P_ENABLE;
  LPCmd.LPDcsShortReadNoP = DSI_LP_DSR0P_ENABLE;
  LPCmd.LPDcsLongWrite = DSI_LP_DLW_ENABLE;
  LPCmd.LPMaxReadPacket = DSI_LP_MRDP_ENABLE;
  LPCmd.AcknowledgeRequest = DSI_ACKNOWLEDGE_ENABLE;
  if (HAL_DSI_ConfigCommand(&hdsi, &LPCmd) != HAL_OK)
  {
    Error_Handler();
  }
  CmdCfg.VirtualChannelID = 0;
  CmdCfg.ColorCoding = DSI_RGB565;
  CmdCfg.CommandSize = 200;
  CmdCfg.TearingEffectSource = DSI_TE_EXTERNAL;
  CmdCfg.TearingEffectPolarity = DSI_TE_RISING_EDGE;
  CmdCfg.HSPolarity = DSI_HSYNC_ACTIVE_LOW;
  CmdCfg.VSPolarity = DSI_VSYNC_ACTIVE_LOW;
  CmdCfg.DEPolarity = DSI_DATA_ENABLE_ACTIVE_HIGH;
  CmdCfg.VSyncPol = DSI_VSYNC_FALLING;
  CmdCfg.AutomaticRefresh = DSI_AR_DISABLE;
  CmdCfg.TEAcknowledgeRequest = DSI_TE_ACKNOWLEDGE_ENABLE;
  if (HAL_DSI_ConfigAdaptedCommandMode(&hdsi, &CmdCfg) != HAL_OK)
  {
    Error_Handler();
  }
  if (HAL_DSI_SetGenericVCID(&hdsi, 0) != HAL_OK)
  {
    Error_Handler();
  }

}

void MX_I2C4_Init(void)
{

  hi2c4.Instance = I2C4;
  hi2c4.Init.Timing = 0x00C0EAFF;
  hi2c4.Init.OwnAddress1 = 0;
  hi2c4.Init.AddressingMode = I2C_ADDRESSINGMODE_7BIT;
  hi2c4.Init.DualAddressMode = I2C_DUALADDRESS_DISABLE;
  hi2c4.Init.OwnAddress2 = 0;
  hi2c4.Init.OwnAddress2Masks = I2C_OA2_NOMASK;
  hi2c4.Init.GeneralCallMode = I2C_GENERALCALL_DISABLE;
  hi2c4.Init.NoStretchMode = I2C_NOSTRETCH_DISABLE;
  if (HAL_I2C_Init(&hi2c4) != HAL_OK)
  {
    Error_Handler();
  }

  /** Configure Analogue filter
  */
  if (HAL_I2CEx_ConfigAnalogFilter(&hi2c4, I2C_ANALOGFILTER_ENABLE) != HAL_OK)
  {
    Error_Handler();
  }

  /** Configure Digital filter
  */
  if (HAL_I2CEx_ConfigDigitalFilter(&hi2c4, 0) != HAL_OK)
  {
    Error_Handler();
  }

}

static void MX_JPEG_Init(void)
{

  hjpeg.Instance = JPEG;
  if (HAL_JPEG_Init(&hjpeg) != HAL_OK)
  {
    Error_Handler();
  }

}

static void MX_LTDC_Init(void)
{

  LTDC_LayerCfgTypeDef pLayerCfg = {0};

  hltdc.Instance = LTDC;
  hltdc.Init.HSPolarity = LTDC_HSPOLARITY_AL;
  hltdc.Init.VSPolarity = LTDC_VSPOLARITY_AL;
  hltdc.Init.DEPolarity = LTDC_DEPOLARITY_AL;
  hltdc.Init.PCPolarity = LTDC_PCPOLARITY_IPC;
  hltdc.Init.HorizontalSync = 1;
  hltdc.Init.VerticalSync = 1;
  hltdc.Init.AccumulatedHBP = 2;
  hltdc.Init.AccumulatedVBP = 2;
  hltdc.Init.AccumulatedActiveW = 202;
  hltdc.Init.AccumulatedActiveH = 482;
  hltdc.Init.TotalWidth = 203;
  hltdc.Init.TotalHeigh = 483;
  hltdc.Init.Backcolor.Blue = 0;
  hltdc.Init.Backcolor.Green = 0;
  hltdc.Init.Backcolor.Red = 0;
  if (HAL_LTDC_Init(&hltdc) != HAL_OK)
  {
    Error_Handler();
  }
  pLayerCfg.WindowX0 = 0;
  pLayerCfg.WindowX1 = 200;
  pLayerCfg.WindowY0 = 0;
  pLayerCfg.WindowY1 = 480;
  pLayerCfg.PixelFormat = LTDC_PIXEL_FORMAT_RGB565;
  pLayerCfg.Alpha = 255;
  pLayerCfg.Alpha0 = 0;
  pLayerCfg.BlendingFactor1 = LTDC_BLENDING_FACTOR1_CA;
  pLayerCfg.BlendingFactor2 = LTDC_BLENDING_FACTOR2_CA;
  pLayerCfg.FBStartAdress = 0xC0000000;
  pLayerCfg.ImageWidth = 200;
  pLayerCfg.ImageHeight = 480;
  pLayerCfg.Backcolor.Blue = 0;
  pLayerCfg.Backcolor.Green = 0;
  pLayerCfg.Backcolor.Red = 0;
  if (HAL_LTDC_ConfigLayer(&hltdc, &pLayerCfg, 0) != HAL_OK)
  {
    Error_Handler();
  }
  /* USER CODE BEGIN LTDC_Init 2 */
  __HAL_LTDC_DISABLE(&hltdc);
  DSI_LPCmdTypeDef LPCmd;

  HAL_DSI_Start(&hdsi);
  OTM8009A_Init(OTM8009A_FORMAT_RBG565, LCD_ORIENTATION_LANDSCAPE);

  HAL_DSI_ShortWrite(&hdsi, 0, DSI_DCS_SHORT_PKT_WRITE_P1, OTM8009A_CMD_DISPOFF, 0x00);

  LPCmd.LPGenShortWriteNoP = DSI_LP_GSW0P_DISABLE;
  LPCmd.LPGenShortWriteOneP = DSI_LP_GSW1P_DISABLE;
  LPCmd.LPGenShortWriteTwoP = DSI_LP_GSW2P_DISABLE;
  LPCmd.LPGenShortReadNoP = DSI_LP_GSR0P_DISABLE;
  LPCmd.LPGenShortReadOneP = DSI_LP_GSR1P_DISABLE;
  LPCmd.LPGenShortReadTwoP = DSI_LP_GSR2P_DISABLE;
  LPCmd.LPGenLongWrite = DSI_LP_GLW_DISABLE;
  LPCmd.LPDcsShortWriteNoP = DSI_LP_DSW0P_DISABLE;
  LPCmd.LPDcsShortWriteOneP = DSI_LP_DSW1P_DISABLE;
  LPCmd.LPDcsShortReadNoP = DSI_LP_DSR0P_DISABLE;
  LPCmd.LPDcsLongWrite = DSI_LP_DLW_DISABLE;
  HAL_DSI_ConfigCommand(&hdsi, &LPCmd);

  HAL_LTDC_SetPitch(&hltdc, 800, 0);
  __HAL_LTDC_ENABLE(&hltdc);

  // LPCmd.LPGenShortWriteNoP = DSI_LP_GSW0P_DISABLE;
  // LPCmd.LPGenShortWriteOneP = DSI_LP_GSW1P_DISABLE;
  // LPCmd.LPGenShortWriteTwoP = DSI_LP_GSW2P_DISABLE;
  // LPCmd.LPGenShortReadNoP = DSI_LP_GSR0P_DISABLE;
  // LPCmd.LPGenShortReadOneP = DSI_LP_GSR1P_DISABLE;
  // LPCmd.LPGenShortReadTwoP = DSI_LP_GSR2P_DISABLE;
  // LPCmd.LPGenLongWrite = DSI_LP_GLW_DISABLE;
  // LPCmd.LPDcsShortWriteNoP = DSI_LP_DSW0P_DISABLE;
  // LPCmd.LPDcsShortWriteOneP = DSI_LP_DSW1P_DISABLE;
  // LPCmd.LPDcsShortReadNoP = DSI_LP_DSR0P_DISABLE;
  // LPCmd.LPDcsLongWrite = DSI_LP_DLW_DISABLE;
  // HAL_DSI_ConfigCommand(&hdsi, &LPCmd);

  // HAL_DSI_ShortWrite(&hdsi, 0, DSI_DCS_SHORT_PKT_WRITE_P1, OTM8009A_CMD_DISPOFF, 0x00);

  // HAL_LTDC_SetPitch(&hltdc, 800, 0);
  // __HAL_LTDC_ENABLE(&hltdc);

  /* USER CODE END LTDC_Init 2 */

}

static void MX_QUADSPI_Init(void)
{

  /* QUADSPI parameter configuration*/
  hqspi.Instance = QUADSPI;
  hqspi.Init.ClockPrescaler = 1;
  hqspi.Init.FifoThreshold = 16;
  hqspi.Init.SampleShifting = QSPI_SAMPLE_SHIFTING_HALFCYCLE;
  hqspi.Init.FlashSize = 25;
  hqspi.Init.ChipSelectHighTime = QSPI_CS_HIGH_TIME_4_CYCLE;
  hqspi.Init.ClockMode = QSPI_CLOCK_MODE_0;
  hqspi.Init.FlashID = QSPI_FLASH_ID_1;
  hqspi.Init.DualFlash = QSPI_DUALFLASH_DISABLE;
  if (HAL_QSPI_Init(&hqspi) != HAL_OK)
  {
    Error_Handler();
  }
  /* USER CODE BEGIN QUADSPI_Init 2 */
  /* QSPI memory reset */
  if (QSPI_ResetMemory(&hqspi) != QSPI_OK)
  {
    Error_Handler();
  }

  /* Put QSPI memory in QPI mode */
  if( QSPI_EnterMemory_QPI( &hqspi )!=QSPI_OK )
  {
    Error_Handler();
  }

  /* Set the QSPI memory in 4-bytes address mode */
  if (QSPI_EnterFourBytesAddress(&hqspi) != QSPI_OK)
  {
    Error_Handler();
  }

  /* Configuration of the dummy cycles on QSPI memory side */
  if (QSPI_DummyCyclesCfg(&hqspi) != QSPI_OK)
  {
    Error_Handler();
  }

  /* Configuration of the Output driver strength on memory side */
  if( QSPI_OutDrvStrengthCfg( &hqspi ) != QSPI_OK )
  {
    Error_Handler();
  }

  if( BSP_QSPI_EnableMemoryMappedMode(&hqspi) != QSPI_OK )
  {
    Error_Handler();
  }

  /* USER CODE END QUADSPI_Init 2 */

}

static void MX_TIM11_Init(void)
{

  TIM_IC_InitTypeDef sConfigIC = {0};

  htim11.Instance = TIM11;
  htim11.Init.Prescaler = 199;
  htim11.Init.CounterMode = TIM_COUNTERMODE_UP;
  htim11.Init.Period = 0xffff-1;
  htim11.Init.ClockDivision = TIM_CLOCKDIVISION_DIV1;
  htim11.Init.AutoReloadPreload = TIM_AUTORELOAD_PRELOAD_DISABLE;
  if (HAL_TIM_Base_Init(&htim11) != HAL_OK)
  {
    Error_Handler();
  }
  if (HAL_TIM_IC_Init(&htim11) != HAL_OK)
  {
    Error_Handler();
  }
  sConfigIC.ICPolarity = TIM_INPUTCHANNELPOLARITY_RISING;
  sConfigIC.ICSelection = TIM_ICSELECTION_DIRECTTI;
  sConfigIC.ICPrescaler = TIM_ICPSC_DIV1;
  sConfigIC.ICFilter = 0;
  if (HAL_TIM_IC_ConfigChannel(&htim11, &sConfigIC, TIM_CHANNEL_1) != HAL_OK)
  {
    Error_Handler();
  }

}

static void MX_USART1_UART_Init(void)
{

  huart1.Instance = USART1;
  huart1.Init.BaudRate = 115200;
  huart1.Init.WordLength = UART_WORDLENGTH_8B;
  huart1.Init.StopBits = UART_STOPBITS_1;
  huart1.Init.Parity = UART_PARITY_NONE;
  huart1.Init.Mode = UART_MODE_TX_RX;
  huart1.Init.HwFlowCtl = UART_HWCONTROL_NONE;
  huart1.Init.OverSampling = UART_OVERSAMPLING_16;
  huart1.Init.OneBitSampling = UART_ONE_BIT_SAMPLE_DISABLE;
  huart1.AdvancedInit.AdvFeatureInit = UART_ADVFEATURE_NO_INIT;
  if (HAL_UART_Init(&huart1) != HAL_OK)
  {
    Error_Handler();
  }

}

static void MX_DMA_Init(void)
{

  /* DMA controller clock enable */
  __HAL_RCC_DMA2_CLK_ENABLE();

  /* DMA interrupt init */
  /* DMA2_Stream0_IRQn interrupt configuration */
  HAL_NVIC_SetPriority(DMA2_Stream0_IRQn, 5, 0);
  HAL_NVIC_EnableIRQ(DMA2_Stream0_IRQn);
  /* DMA2_Stream1_IRQn interrupt configuration */
  HAL_NVIC_SetPriority(DMA2_Stream1_IRQn, 5, 0);
  HAL_NVIC_EnableIRQ(DMA2_Stream1_IRQn);

}

/* FMC initialization function */
static void MX_FMC_Init(void)
{

  FMC_SDRAM_TimingTypeDef SdramTiming = {0};

  /** Perform the SDRAM1 memory initialization sequence
  */
  hsdram1.Instance = FMC_SDRAM_DEVICE;
  /* hsdram1.Init */
  hsdram1.Init.SDBank = FMC_SDRAM_BANK1;
  hsdram1.Init.ColumnBitsNumber = FMC_SDRAM_COLUMN_BITS_NUM_8;
  hsdram1.Init.RowBitsNumber = FMC_SDRAM_ROW_BITS_NUM_12;
  hsdram1.Init.MemoryDataWidth = FMC_SDRAM_MEM_BUS_WIDTH_32;
  hsdram1.Init.InternalBankNumber = FMC_SDRAM_INTERN_BANKS_NUM_4;
  hsdram1.Init.CASLatency = FMC_SDRAM_CAS_LATENCY_3;
  hsdram1.Init.WriteProtection = FMC_SDRAM_WRITE_PROTECTION_DISABLE;
  hsdram1.Init.SDClockPeriod = FMC_SDRAM_CLOCK_PERIOD_2;
  hsdram1.Init.ReadBurst = FMC_SDRAM_RBURST_ENABLE;
  hsdram1.Init.ReadPipeDelay = FMC_SDRAM_RPIPE_DELAY_0;
  /* SdramTiming */
  SdramTiming.LoadToActiveDelay = 2;
  SdramTiming.ExitSelfRefreshDelay = 7;
  SdramTiming.SelfRefreshTime = 4;
  SdramTiming.RowCycleDelay = 7;
  SdramTiming.WriteRecoveryTime = 2;
  SdramTiming.RPDelay = 2;
  SdramTiming.RCDDelay = 3;

  if (HAL_SDRAM_Init(&hsdram1, &SdramTiming) != HAL_OK)
  {
    Error_Handler( );
  }

  /* USER CODE BEGIN FMC_Init 2 */

  FMC_SDRAM_CommandTypeDef command;

  /* Program the SDRAM external device */
  BSP_SDRAM_Initialization_Sequence(&hsdram1, &command);

  //Deactivate speculative/cache access to first FMC Bank to save FMC bandwidth
  FMC_Bank1->BTCR[0] = 0x000030D2;
  /* USER CODE END FMC_Init 2 */
}

static void MX_GPIO_Init(void)
{
  GPIO_InitTypeDef GPIO_InitStruct = {0};

  /* GPIO Ports Clock Enable */
  __HAL_RCC_GPIOE_CLK_ENABLE();
  __HAL_RCC_GPIOB_CLK_ENABLE();
  __HAL_RCC_GPIOG_CLK_ENABLE();
  __HAL_RCC_GPIOD_CLK_ENABLE();
  __HAL_RCC_GPIOC_CLK_ENABLE();
  __HAL_RCC_GPIOI_CLK_ENABLE();
  __HAL_RCC_GPIOF_CLK_ENABLE();
  __HAL_RCC_GPIOJ_CLK_ENABLE();
  __HAL_RCC_GPIOH_CLK_ENABLE();
  __HAL_RCC_GPIOA_CLK_ENABLE();

  /*Configure GPIO pin Output Level */
  HAL_GPIO_WritePin(DSI_RESET_GPIO_Port, DSI_RESET_Pin, GPIO_PIN_SET);

  /*Configure GPIO pin Output Level */
  HAL_GPIO_WritePin(GPIOC, RENDER_TIME_Pin|VSYNC_FREQ_Pin, GPIO_PIN_RESET);

  /*Configure GPIO pin Output Level */
  HAL_GPIO_WritePin(MCU_ACTIVE_GPIO_Port, MCU_ACTIVE_Pin, GPIO_PIN_RESET);

  /*Configure GPIO pin Output Level */
  HAL_GPIO_WritePin(GPIOJ, GPIO_PIN_3|FRAME_RATE_Pin, GPIO_PIN_RESET);

  /*Configure GPIO pin : DSI_RESET_Pin */
  GPIO_InitStruct.Pin = DSI_RESET_Pin;
  GPIO_InitStruct.Mode = GPIO_MODE_OUTPUT_PP;
  GPIO_InitStruct.Pull = GPIO_PULLUP;
  GPIO_InitStruct.Speed = GPIO_SPEED_FREQ_MEDIUM;
  HAL_GPIO_Init(DSI_RESET_GPIO_Port, &GPIO_InitStruct);

  /*Configure GPIO pins : RENDER_TIME_Pin VSYNC_FREQ_Pin */
  GPIO_InitStruct.Pin = RENDER_TIME_Pin|VSYNC_FREQ_Pin;
  GPIO_InitStruct.Mode = GPIO_MODE_OUTPUT_PP;
  GPIO_InitStruct.Pull = GPIO_NOPULL;
  GPIO_InitStruct.Speed = GPIO_SPEED_FREQ_VERY_HIGH;
  HAL_GPIO_Init(GPIOC, &GPIO_InitStruct);

  /*Configure GPIO pin : MCU_ACTIVE_Pin */
  GPIO_InitStruct.Pin = MCU_ACTIVE_Pin;
  GPIO_InitStruct.Mode = GPIO_MODE_OUTPUT_PP;
  GPIO_InitStruct.Pull = GPIO_NOPULL;
  GPIO_InitStruct.Speed = GPIO_SPEED_FREQ_VERY_HIGH;
  HAL_GPIO_Init(MCU_ACTIVE_GPIO_Port, &GPIO_InitStruct);

  /*Configure GPIO pin : PA0 */
  GPIO_InitStruct.Pin = GPIO_PIN_0;
  GPIO_InitStruct.Mode = GPIO_MODE_IT_RISING;
  GPIO_InitStruct.Pull = GPIO_NOPULL;
  HAL_GPIO_Init(GPIOA, &GPIO_InitStruct);

  /*Configure GPIO pin : PJ3 */
  GPIO_InitStruct.Pin = GPIO_PIN_3;
  GPIO_InitStruct.Mode = GPIO_MODE_OUTPUT_PP;
  GPIO_InitStruct.Pull = GPIO_NOPULL;
  GPIO_InitStruct.Speed = GPIO_SPEED_FREQ_LOW;
  HAL_GPIO_Init(GPIOJ, &GPIO_InitStruct);

  /*Configure GPIO pin : FRAME_RATE_Pin */
  GPIO_InitStruct.Pin = FRAME_RATE_Pin;
  GPIO_InitStruct.Mode = GPIO_MODE_OUTPUT_PP;
  GPIO_InitStruct.Pull = GPIO_NOPULL;
  GPIO_InitStruct.Speed = GPIO_SPEED_FREQ_VERY_HIGH;
  HAL_GPIO_Init(FRAME_RATE_GPIO_Port, &GPIO_InitStruct);

  /* EXTI interrupt init*/
  HAL_NVIC_SetPriority(EXTI0_IRQn, 5, 0);
  HAL_NVIC_EnableIRQ(EXTI0_IRQn);

}

/* USER CODE BEGIN 4 */
/**
  * @brief  Perform the SDRAM external memory initialization sequence
  * @param  hsdram: SDRAM handle
  * @param  Command: Pointer to SDRAM command structure
  * @retval None
  */
static void BSP_SDRAM_Initialization_Sequence(SDRAM_HandleTypeDef *hsdram, FMC_SDRAM_CommandTypeDef *Command)
{
 __IO uint32_t tmpmrd = 0;

    /* Step 1: Configure a clock configuration enable command */
    Command->CommandMode            = FMC_SDRAM_CMD_CLK_ENABLE;
    Command->CommandTarget          =  FMC_SDRAM_CMD_TARGET_BANK1;
    Command->AutoRefreshNumber      = 1;
    Command->ModeRegisterDefinition = 0;

    /* Send the command */
    HAL_SDRAM_SendCommand(hsdram, Command, SDRAM_TIMEOUT);

    /* Step 2: Insert 100 us minimum delay */
    /* Inserted delay is equal to 1 ms due to systick time base unit (ms) */
    HAL_Delay(1);

    /* Step 3: Configure a PALL (precharge all) command */
    Command->CommandMode            = FMC_SDRAM_CMD_PALL;
    Command->CommandTarget          = FMC_SDRAM_CMD_TARGET_BANK1;
    Command->AutoRefreshNumber      = 1;
    Command->ModeRegisterDefinition = 0;

    /* Send the command */
    HAL_SDRAM_SendCommand(hsdram, Command, SDRAM_TIMEOUT);

    /* Step 4: Configure an Auto Refresh command */
    Command->CommandMode            = FMC_SDRAM_CMD_AUTOREFRESH_MODE;
    Command->CommandTarget          = FMC_SDRAM_CMD_TARGET_BANK1;
    Command->AutoRefreshNumber      = 8;
    Command->ModeRegisterDefinition = 0;

    /* Send the command */
    HAL_SDRAM_SendCommand(hsdram, Command, SDRAM_TIMEOUT);

    /* Step 5: Program the external memory mode register */
    tmpmrd = (uint32_t)SDRAM_MODEREG_BURST_LENGTH_1          | \
             SDRAM_MODEREG_BURST_TYPE_SEQUENTIAL   | \
             SDRAM_MODEREG_CAS_LATENCY_3           | \
             SDRAM_MODEREG_OPERATING_MODE_STANDARD | \
             SDRAM_MODEREG_WRITEBURST_MODE_SINGLE;

    Command->CommandMode            = FMC_SDRAM_CMD_LOAD_MODE;
    Command->CommandTarget          = FMC_SDRAM_CMD_TARGET_BANK1;
    Command->AutoRefreshNumber      = 1;
    Command->ModeRegisterDefinition = tmpmrd;

    /* Send the command */
    HAL_SDRAM_SendCommand(hsdram, Command, SDRAM_TIMEOUT);

    /* Step 6: Set the refresh rate counter */
    /* Set the device refresh rate */
    HAL_SDRAM_ProgramRefreshRate(hsdram, REFRESH_COUNT);

}

/**
  * @brief  This function reset the QSPI memory.
  * @param  hqspi: QSPI handle
  * @retval None
  */
static uint8_t QSPI_ResetMemory(QSPI_HandleTypeDef *hqspi)
{
  QSPI_CommandTypeDef      s_command;
  QSPI_AutoPollingTypeDef  s_config;
  uint8_t                  reg;

  /* Send command RESET command in QPI mode (QUAD I/Os) */
  /* Initialize the reset enable command */
  s_command.InstructionMode   = QSPI_INSTRUCTION_4_LINES;
  s_command.Instruction       = RESET_ENABLE_CMD;
  s_command.AddressMode       = QSPI_ADDRESS_NONE;
  s_command.AlternateByteMode = QSPI_ALTERNATE_BYTES_NONE;
  s_command.DataMode          = QSPI_DATA_NONE;
  s_command.DummyCycles       = 0;
  s_command.DdrMode           = QSPI_DDR_MODE_DISABLE;
  s_command.DdrHoldHalfCycle  = QSPI_DDR_HHC_ANALOG_DELAY;
  s_command.SIOOMode          = QSPI_SIOO_INST_EVERY_CMD;
  /* Send the command */
  if (HAL_QSPI_Command(hqspi, &s_command, HAL_QPSI_TIMEOUT_DEFAULT_VALUE) != HAL_OK)
  {
    return QSPI_ERROR;
  }
  /* Send the reset memory command */
  s_command.Instruction = RESET_MEMORY_CMD;
  if (HAL_QSPI_Command(hqspi, &s_command, HAL_QPSI_TIMEOUT_DEFAULT_VALUE) != HAL_OK)
  {
    return QSPI_ERROR;
  }

  /* Send command RESET command in SPI mode */
  /* Initialize the reset enable command */
  s_command.InstructionMode   = QSPI_INSTRUCTION_1_LINE;
  s_command.Instruction       = RESET_ENABLE_CMD;
  /* Send the command */
  if (HAL_QSPI_Command(hqspi, &s_command, HAL_QPSI_TIMEOUT_DEFAULT_VALUE) != HAL_OK)
  {
    return QSPI_ERROR;
  }
  /* Send the reset memory command */
  s_command.Instruction = RESET_MEMORY_CMD;
  if (HAL_QSPI_Command(hqspi, &s_command, HAL_QPSI_TIMEOUT_DEFAULT_VALUE) != HAL_OK)
  {
    return QSPI_ERROR;
  }

  /* After reset CMD, 1000ms requested if QSPI memory SWReset occured during full chip erase operation */
  HAL_Delay( 1000 );

  /* Configure automatic polling mode to wait the WIP bit=0 */
  s_config.Match           = 0;
  s_config.Mask            = MX25L512_SR_WIP;
  s_config.MatchMode       = QSPI_MATCH_MODE_AND;
  s_config.StatusBytesSize = 1;
  s_config.Interval        = 0x10;
  s_config.AutomaticStop   = QSPI_AUTOMATIC_STOP_ENABLE;

  s_command.InstructionMode = QSPI_INSTRUCTION_1_LINE;
  s_command.Instruction     = READ_STATUS_REG_CMD;
  s_command.DataMode        = QSPI_DATA_1_LINE;

  if (HAL_QSPI_AutoPolling(hqspi, &s_command, &s_config, HAL_QPSI_TIMEOUT_DEFAULT_VALUE) != HAL_OK)
  {
    return QSPI_ERROR;
  }

  /* Initialize the reading of status register */
  s_command.InstructionMode   = QSPI_INSTRUCTION_1_LINE;
  s_command.Instruction       = READ_STATUS_REG_CMD;
  s_command.AddressMode       = QSPI_ADDRESS_NONE;
  s_command.AlternateByteMode = QSPI_ALTERNATE_BYTES_NONE;
  s_command.DataMode          = QSPI_DATA_1_LINE;
  s_command.DummyCycles       = 0;
  s_command.NbData            = 1;
  s_command.DdrMode           = QSPI_DDR_MODE_DISABLE;
  s_command.DdrHoldHalfCycle  = QSPI_DDR_HHC_ANALOG_DELAY;
  s_command.SIOOMode          = QSPI_SIOO_INST_EVERY_CMD;

  /* Configure the command */
  if (HAL_QSPI_Command(hqspi, &s_command, HAL_QPSI_TIMEOUT_DEFAULT_VALUE) != HAL_OK)
  {
    return QSPI_ERROR;
  }

  /* Reception of the data */
  if (HAL_QSPI_Receive(hqspi, &reg, HAL_QPSI_TIMEOUT_DEFAULT_VALUE) != HAL_OK)
  {
    return QSPI_ERROR;
  }

  /* Enable write operations, command in 1 bit */
  /* Enable write operations */
  s_command.InstructionMode   = QSPI_INSTRUCTION_1_LINE;
  s_command.Instruction       = WRITE_ENABLE_CMD;
  s_command.AddressMode       = QSPI_ADDRESS_NONE;
  s_command.AlternateByteMode = QSPI_ALTERNATE_BYTES_NONE;
  s_command.DataMode          = QSPI_DATA_NONE;
  s_command.DummyCycles       = 0;
  s_command.DdrMode           = QSPI_DDR_MODE_DISABLE;
  s_command.DdrHoldHalfCycle  = QSPI_DDR_HHC_ANALOG_DELAY;
  s_command.SIOOMode          = QSPI_SIOO_INST_EVERY_CMD;

  if (HAL_QSPI_Command(hqspi, &s_command, HAL_QPSI_TIMEOUT_DEFAULT_VALUE) != HAL_OK)
  {
    return QSPI_ERROR;
  }

  /* Configure automatic polling mode to wait for write enabling */
  s_config.Match           = MX25L512_SR_WREN;
  s_config.Mask            = MX25L512_SR_WREN;
  s_config.MatchMode       = QSPI_MATCH_MODE_AND;
  s_config.StatusBytesSize = 1;
  s_config.Interval        = 0x10;
  s_config.AutomaticStop   = QSPI_AUTOMATIC_STOP_ENABLE;

  s_command.Instruction    = READ_STATUS_REG_CMD;
  s_command.DataMode       = QSPI_DATA_1_LINE;

  if (HAL_QSPI_AutoPolling(hqspi, &s_command, &s_config, HAL_QPSI_TIMEOUT_DEFAULT_VALUE) != HAL_OK)
  {
    return QSPI_ERROR;
  }

  /* Update the configuration register with new dummy cycles */
  s_command.InstructionMode   = QSPI_INSTRUCTION_1_LINE;
  s_command.Instruction       = WRITE_STATUS_CFG_REG_CMD;
  s_command.AddressMode       = QSPI_ADDRESS_NONE;
  s_command.AlternateByteMode = QSPI_ALTERNATE_BYTES_NONE;
  s_command.DataMode          = QSPI_DATA_1_LINE;
  s_command.DummyCycles       = 0;
  s_command.NbData            = 1;
  s_command.DdrMode           = QSPI_DDR_MODE_DISABLE;
  s_command.DdrHoldHalfCycle  = QSPI_DDR_HHC_ANALOG_DELAY;
  s_command.SIOOMode          = QSPI_SIOO_INST_EVERY_CMD;

  /* Enable the Quad IO on the QSPI memory (Non-volatile bit) */
  reg |= MX25L512_SR_QUADEN;

  /* Configure the command */
  if (HAL_QSPI_Command(hqspi, &s_command, HAL_QPSI_TIMEOUT_DEFAULT_VALUE) != HAL_OK)
  {
    return QSPI_ERROR;
  }

  /* Transmission of the data */
  if (HAL_QSPI_Transmit(hqspi, &reg, HAL_QPSI_TIMEOUT_DEFAULT_VALUE) != HAL_OK)
  {
    return QSPI_ERROR;
  }

  /* 40ms  Write Status/Configuration Register Cycle Time */
  HAL_Delay( 40 );

  return QSPI_OK;
}

/**
  * @brief  This function put QSPI memory in QPI mode (quad I/O).
  * @param  hqspi: QSPI handle
  * @retval None
  */
static uint8_t QSPI_EnterMemory_QPI( QSPI_HandleTypeDef *hqspi )
{
  QSPI_CommandTypeDef      s_command;
  QSPI_AutoPollingTypeDef  s_config;

  /* Initialize the QPI enable command */
  /* QSPI memory is supported to be in SPI mode, so CMD on 1 LINE */
  s_command.InstructionMode   = QSPI_INSTRUCTION_1_LINE;
  s_command.Instruction       = ENTER_QUAD_CMD;
  s_command.AddressMode       = QSPI_ADDRESS_NONE;
  s_command.AlternateByteMode = QSPI_ALTERNATE_BYTES_NONE;
  s_command.DataMode          = QSPI_DATA_NONE;
  s_command.DummyCycles       = 0;
  s_command.DdrMode           = QSPI_DDR_MODE_DISABLE;
  s_command.DdrHoldHalfCycle  = QSPI_DDR_HHC_ANALOG_DELAY;
  s_command.SIOOMode          = QSPI_SIOO_INST_EVERY_CMD;

  /* Send the command */
  if (HAL_QSPI_Command(hqspi, &s_command, HAL_QPSI_TIMEOUT_DEFAULT_VALUE) != HAL_OK)
  {
    return QSPI_ERROR;
  }

  /* Configure automatic polling mode to wait the QUADEN bit=1 and WIP bit=0 */
  s_config.Match           = MX25L512_SR_QUADEN;
  s_config.Mask            = MX25L512_SR_QUADEN|MX25L512_SR_WIP;
  s_config.MatchMode       = QSPI_MATCH_MODE_AND;
  s_config.StatusBytesSize = 1;
  s_config.Interval        = 0x10;
  s_config.AutomaticStop   = QSPI_AUTOMATIC_STOP_ENABLE;

  s_command.InstructionMode   = QSPI_INSTRUCTION_4_LINES;
  s_command.Instruction       = READ_STATUS_REG_CMD;
  s_command.DataMode          = QSPI_DATA_4_LINES;

  if (HAL_QSPI_AutoPolling(hqspi, &s_command, &s_config, HAL_QPSI_TIMEOUT_DEFAULT_VALUE) != HAL_OK)
  {
    return QSPI_ERROR;
  }

  return QSPI_OK;
}

/**
  * @brief  This function set the QSPI memory in 4-byte address mode
  * @param  hqspi: QSPI handle
  * @retval None
  */
static uint8_t QSPI_EnterFourBytesAddress(QSPI_HandleTypeDef *hqspi)
{
  QSPI_CommandTypeDef s_command;

  /* Initialize the command */
  s_command.InstructionMode   = QSPI_INSTRUCTION_4_LINES;
  s_command.Instruction       = ENTER_4_BYTE_ADDR_MODE_CMD;
  s_command.AddressMode       = QSPI_ADDRESS_NONE;
  s_command.AlternateByteMode = QSPI_ALTERNATE_BYTES_NONE;
  s_command.DataMode          = QSPI_DATA_NONE;
  s_command.DummyCycles       = 0;
  s_command.DdrMode           = QSPI_DDR_MODE_DISABLE;
  s_command.DdrHoldHalfCycle  = QSPI_DDR_HHC_ANALOG_DELAY;
  s_command.SIOOMode          = QSPI_SIOO_INST_EVERY_CMD;

  /* Enable write operations */
  if (QSPI_WriteEnable(hqspi) != QSPI_OK)
  {
    return QSPI_ERROR;
  }

  /* Send the command */
  if (HAL_QSPI_Command(hqspi, &s_command, HAL_QPSI_TIMEOUT_DEFAULT_VALUE) != HAL_OK)
  {
    return QSPI_ERROR;
  }

  /* Configure automatic polling mode to wait the memory is ready */
  if (QSPI_AutoPollingMemReady(hqspi, HAL_QPSI_TIMEOUT_DEFAULT_VALUE) != QSPI_OK)
  {
    return QSPI_ERROR;
  }

  return QSPI_OK;
}

/**
  * @brief  This function configure the dummy cycles on memory side.
  * @param  hqspi: QSPI handle
  * @retval None
  */
static uint8_t QSPI_DummyCyclesCfg(QSPI_HandleTypeDef *hqspi)
{
  QSPI_CommandTypeDef s_command;
  uint8_t reg[2];

  /* Initialize the reading of status register */
  s_command.InstructionMode   = QSPI_INSTRUCTION_4_LINES;
  s_command.Instruction       = READ_STATUS_REG_CMD;
  s_command.AddressMode       = QSPI_ADDRESS_NONE;
  s_command.AlternateByteMode = QSPI_ALTERNATE_BYTES_NONE;
  s_command.DataMode          = QSPI_DATA_4_LINES;
  s_command.DummyCycles       = 0;
  s_command.NbData            = 1;
  s_command.DdrMode           = QSPI_DDR_MODE_DISABLE;
  s_command.DdrHoldHalfCycle  = QSPI_DDR_HHC_ANALOG_DELAY;
  s_command.SIOOMode          = QSPI_SIOO_INST_EVERY_CMD;

  /* Configure the command */
  if (HAL_QSPI_Command(hqspi, &s_command, HAL_QPSI_TIMEOUT_DEFAULT_VALUE) != HAL_OK)
  {
    return QSPI_ERROR;
  }

  /* Reception of the data */
  if (HAL_QSPI_Receive(hqspi, &(reg[0]), HAL_QPSI_TIMEOUT_DEFAULT_VALUE) != HAL_OK)
  {
    return QSPI_ERROR;
  }

  /* Initialize the reading of configuration register */
  s_command.InstructionMode   = QSPI_INSTRUCTION_4_LINES;
  s_command.Instruction       = READ_CFG_REG_CMD;
  s_command.AddressMode       = QSPI_ADDRESS_NONE;
  s_command.AlternateByteMode = QSPI_ALTERNATE_BYTES_NONE;
  s_command.DataMode          = QSPI_DATA_4_LINES;
  s_command.DummyCycles       = 0;
  s_command.NbData            = 1;
  s_command.DdrMode           = QSPI_DDR_MODE_DISABLE;
  s_command.DdrHoldHalfCycle  = QSPI_DDR_HHC_ANALOG_DELAY;
  s_command.SIOOMode          = QSPI_SIOO_INST_EVERY_CMD;

  /* Configure the command */
  if (HAL_QSPI_Command(hqspi, &s_command, HAL_QPSI_TIMEOUT_DEFAULT_VALUE) != HAL_OK)
  {
    return QSPI_ERROR;
  }

  /* Reception of the data */
  if (HAL_QSPI_Receive(hqspi, &(reg[1]), HAL_QPSI_TIMEOUT_DEFAULT_VALUE) != HAL_OK)
  {
    return QSPI_ERROR;
  }

  /* Enable write operations */
  if (QSPI_WriteEnable(hqspi) != QSPI_OK)
  {
    return QSPI_ERROR;
  }

  /* Update the configuration register with new dummy cycles */
  s_command.InstructionMode   = QSPI_INSTRUCTION_4_LINES;
  s_command.Instruction       = WRITE_STATUS_CFG_REG_CMD;
  s_command.AddressMode       = QSPI_ADDRESS_NONE;
  s_command.AlternateByteMode = QSPI_ALTERNATE_BYTES_NONE;
  s_command.DataMode          = QSPI_DATA_4_LINES;
  s_command.DummyCycles       = 0;
  s_command.NbData            = 2;
  s_command.DdrMode           = QSPI_DDR_MODE_DISABLE;
  s_command.DdrHoldHalfCycle  = QSPI_DDR_HHC_ANALOG_DELAY;
  s_command.SIOOMode          = QSPI_SIOO_INST_EVERY_CMD;

  /* MX25L512_DUMMY_CYCLES_READ_QUAD = 3 for 10 cycles in QPI mode */
  MODIFY_REG( reg[1], MX25L512_CR_NB_DUMMY, (MX25L512_DUMMY_CYCLES_READ_QUAD << POSITION_VAL(MX25L512_CR_NB_DUMMY)));

  /* Configure the write volatile configuration register command */
  if (HAL_QSPI_Command(hqspi, &s_command, HAL_QPSI_TIMEOUT_DEFAULT_VALUE) != HAL_OK)
  {
    return QSPI_ERROR;
  }

  /* Transmission of the data */
  if (HAL_QSPI_Transmit(hqspi, &(reg[0]), HAL_QPSI_TIMEOUT_DEFAULT_VALUE) != HAL_OK)
  {
    return QSPI_ERROR;
  }

  /* 40ms  Write Status/Configuration Register Cycle Time */
  HAL_Delay( 40 );

  return QSPI_OK;
}

/**
  * @brief  This function configure the Output driver strength on memory side.
  * @param  hqspi: QSPI handle
  * @retval None
  */
static uint8_t QSPI_OutDrvStrengthCfg( QSPI_HandleTypeDef *hqspi )
{
  QSPI_CommandTypeDef s_command;
  uint8_t reg[2];

  /* Initialize the reading of status register */
  s_command.InstructionMode   = QSPI_INSTRUCTION_4_LINES;
  s_command.Instruction       = READ_STATUS_REG_CMD;
  s_command.AddressMode       = QSPI_ADDRESS_NONE;
  s_command.AlternateByteMode = QSPI_ALTERNATE_BYTES_NONE;
  s_command.DataMode          = QSPI_DATA_4_LINES;
  s_command.DummyCycles       = 0;
  s_command.NbData            = 1;
  s_command.DdrMode           = QSPI_DDR_MODE_DISABLE;
  s_command.DdrHoldHalfCycle  = QSPI_DDR_HHC_ANALOG_DELAY;
  s_command.SIOOMode          = QSPI_SIOO_INST_EVERY_CMD;

  /* Configure the command */
  if (HAL_QSPI_Command(hqspi, &s_command, HAL_QPSI_TIMEOUT_DEFAULT_VALUE) != HAL_OK)
  {
    return QSPI_ERROR;
  }

  /* Reception of the data */
  if (HAL_QSPI_Receive(hqspi, &(reg[0]), HAL_QPSI_TIMEOUT_DEFAULT_VALUE) != HAL_OK)
  {
    return QSPI_ERROR;
  }

  /* Initialize the reading of configuration register */
  s_command.InstructionMode   = QSPI_INSTRUCTION_4_LINES;
  s_command.Instruction       = READ_CFG_REG_CMD;
  s_command.AddressMode       = QSPI_ADDRESS_NONE;
  s_command.AlternateByteMode = QSPI_ALTERNATE_BYTES_NONE;
  s_command.DataMode          = QSPI_DATA_4_LINES;
  s_command.DummyCycles       = 0;
  s_command.NbData            = 1;
  s_command.DdrMode           = QSPI_DDR_MODE_DISABLE;
  s_command.DdrHoldHalfCycle  = QSPI_DDR_HHC_ANALOG_DELAY;
  s_command.SIOOMode          = QSPI_SIOO_INST_EVERY_CMD;

  /* Configure the command */
  if (HAL_QSPI_Command(hqspi, &s_command, HAL_QPSI_TIMEOUT_DEFAULT_VALUE) != HAL_OK)
  {
    return QSPI_ERROR;
  }

  /* Reception of the data */
  if (HAL_QSPI_Receive(hqspi, &(reg[1]), HAL_QPSI_TIMEOUT_DEFAULT_VALUE) != HAL_OK)
  {
    return QSPI_ERROR;
  }

  /* Enable write operations */
  if (QSPI_WriteEnable(hqspi) != QSPI_OK)
  {
    return QSPI_ERROR;
  }

  /* Update the configuration register with new output driver strength */
  s_command.InstructionMode   = QSPI_INSTRUCTION_4_LINES;
  s_command.Instruction       = WRITE_STATUS_CFG_REG_CMD;
  s_command.AddressMode       = QSPI_ADDRESS_NONE;
  s_command.AlternateByteMode = QSPI_ALTERNATE_BYTES_NONE;
  s_command.DataMode          = QSPI_DATA_4_LINES;
  s_command.DummyCycles       = 0;
  s_command.NbData            = 2;
  s_command.DdrMode           = QSPI_DDR_MODE_DISABLE;
  s_command.DdrHoldHalfCycle  = QSPI_DDR_HHC_ANALOG_DELAY;
  s_command.SIOOMode          = QSPI_SIOO_INST_EVERY_CMD;

  /* Set Output Strength of the QSPI memory 15 ohms */
  MODIFY_REG( reg[1], MX25L512_CR_ODS, (MX25L512_CR_ODS_15 << POSITION_VAL(MX25L512_CR_ODS)));

  /* Configure the write volatile configuration register command */
  if (HAL_QSPI_Command(hqspi, &s_command, HAL_QPSI_TIMEOUT_DEFAULT_VALUE) != HAL_OK)
  {
    return QSPI_ERROR;
  }

  /* Transmission of the data */
  if (HAL_QSPI_Transmit(hqspi, &(reg[0]), HAL_QPSI_TIMEOUT_DEFAULT_VALUE) != HAL_OK)
  {
    return QSPI_ERROR;
  }

  return QSPI_OK;
}

/**
  * @brief  This function send a Write Enable and wait it is effective.
  * @param  hqspi: QSPI handle
  * @retval None
  */
static uint8_t QSPI_WriteEnable(QSPI_HandleTypeDef *hqspi)
{
  QSPI_CommandTypeDef     s_command;
  QSPI_AutoPollingTypeDef s_config;

  /* Enable write operations */
  s_command.InstructionMode   = QSPI_INSTRUCTION_4_LINES;
  s_command.Instruction       = WRITE_ENABLE_CMD;
  s_command.AddressMode       = QSPI_ADDRESS_NONE;
  s_command.AlternateByteMode = QSPI_ALTERNATE_BYTES_NONE;
  s_command.DataMode          = QSPI_DATA_NONE;
  s_command.DummyCycles       = 0;
  s_command.DdrMode           = QSPI_DDR_MODE_DISABLE;
  s_command.DdrHoldHalfCycle  = QSPI_DDR_HHC_ANALOG_DELAY;
  s_command.SIOOMode          = QSPI_SIOO_INST_EVERY_CMD;

  if (HAL_QSPI_Command(hqspi, &s_command, HAL_QPSI_TIMEOUT_DEFAULT_VALUE) != HAL_OK)
  {
    return QSPI_ERROR;
  }

  /* Configure automatic polling mode to wait for write enabling */
  s_config.Match           = MX25L512_SR_WREN;
  s_config.Mask            = MX25L512_SR_WREN;
  s_config.MatchMode       = QSPI_MATCH_MODE_AND;
  s_config.StatusBytesSize = 1;
  s_config.Interval        = 0x10;
  s_config.AutomaticStop   = QSPI_AUTOMATIC_STOP_ENABLE;

  s_command.Instruction    = READ_STATUS_REG_CMD;
  s_command.DataMode       = QSPI_DATA_4_LINES;

  if (HAL_QSPI_AutoPolling(hqspi, &s_command, &s_config, HAL_QPSI_TIMEOUT_DEFAULT_VALUE) != HAL_OK)
  {
    return QSPI_ERROR;
  }

  return QSPI_OK;
}

/**
  * @brief  This function read the SR of the memory and wait the EOP.
  * @param  hqspi: QSPI handle
  * @param  Timeout
  * @retval None
  */
static uint8_t QSPI_AutoPollingMemReady(QSPI_HandleTypeDef *hqspi, uint32_t Timeout)
{
  QSPI_CommandTypeDef     s_command;
  QSPI_AutoPollingTypeDef s_config;

  /* Configure automatic polling mode to wait for memory ready */
  s_command.InstructionMode   = QSPI_INSTRUCTION_4_LINES;
  s_command.Instruction       = READ_STATUS_REG_CMD;
  s_command.AddressMode       = QSPI_ADDRESS_NONE;
  s_command.AlternateByteMode = QSPI_ALTERNATE_BYTES_NONE;
  s_command.DataMode          = QSPI_DATA_4_LINES;
  s_command.DummyCycles       = 0;
  s_command.DdrMode           = QSPI_DDR_MODE_DISABLE;
  s_command.DdrHoldHalfCycle  = QSPI_DDR_HHC_ANALOG_DELAY;
  s_command.SIOOMode          = QSPI_SIOO_INST_EVERY_CMD;

  s_config.Match           = 0;
  s_config.Mask            = MX25L512_SR_WIP;
  s_config.MatchMode       = QSPI_MATCH_MODE_AND;
  s_config.StatusBytesSize = 1;
  s_config.Interval        = 0x10;
  s_config.AutomaticStop   = QSPI_AUTOMATIC_STOP_ENABLE;

  if (HAL_QSPI_AutoPolling(hqspi, &s_command, &s_config, Timeout) != HAL_OK)
  {
    return QSPI_ERROR;
  }

  return QSPI_OK;
}

/**
  * @brief  Configure the QSPI in memory-mapped mode
  * @retval QSPI memory status
  */
static uint8_t BSP_QSPI_EnableMemoryMappedMode(QSPI_HandleTypeDef *hqspi)
{
  QSPI_CommandTypeDef      s_command;
  QSPI_MemoryMappedTypeDef s_mem_mapped_cfg;

  /* Configure the command for the read instruction */
  s_command.InstructionMode   = QSPI_INSTRUCTION_4_LINES;
  s_command.Instruction       = QPI_READ_4_BYTE_ADDR_CMD;
  s_command.AddressMode       = QSPI_ADDRESS_4_LINES;
  s_command.AddressSize       = QSPI_ADDRESS_32_BITS;
  s_command.AlternateByteMode = QSPI_ALTERNATE_BYTES_NONE;
  s_command.DataMode          = QSPI_DATA_4_LINES;
  s_command.DummyCycles       = MX25L512_DUMMY_CYCLES_READ_QUAD_IO;
  s_command.DdrMode           = QSPI_DDR_MODE_DISABLE;
  s_command.DdrHoldHalfCycle  = QSPI_DDR_HHC_ANALOG_DELAY;
  s_command.SIOOMode          = QSPI_SIOO_INST_EVERY_CMD;

  /* Configure the memory mapped mode */
  s_mem_mapped_cfg.TimeOutActivation = QSPI_TIMEOUT_COUNTER_DISABLE;
  s_mem_mapped_cfg.TimeOutPeriod     = 0;

  if (HAL_QSPI_MemoryMapped(hqspi, &s_command, &s_mem_mapped_cfg) != HAL_OK)
  {
    return QSPI_ERROR;
  }

  return QSPI_OK;
}

/* USER CODE END 4 */

void StartDefaultTask(void *argument)
{
  /* USER CODE BEGIN 5 */

  for(;;)
  {
    osDelay(100);
  }

}
//    /* USER CODE BEGIN 5 */
void sensorTaskFunc(void *argument)
{
	while(1)
	{
		DHT22_Loop();
		osDelay(0);
	}
}
//    /* USER CODE END 5 */

  /* USER CODE END 5 */

/* MPU Configuration */

void MPU_Config(void)
{
  MPU_Region_InitTypeDef MPU_InitStruct = {0};

  /* Disables the MPU */
  HAL_MPU_Disable();

  /** Initializes and configures the Region and the memory to be protected
  */
  MPU_InitStruct.Enable = MPU_REGION_ENABLE;
  MPU_InitStruct.Number = MPU_REGION_NUMBER0;
  MPU_InitStruct.BaseAddress = 0x20000000;
  MPU_InitStruct.Size = MPU_REGION_SIZE_512KB;
  MPU_InitStruct.SubRegionDisable = 0x0;
  MPU_InitStruct.TypeExtField = MPU_TEX_LEVEL0;
  MPU_InitStruct.AccessPermission = MPU_REGION_FULL_ACCESS;
  MPU_InitStruct.DisableExec = MPU_INSTRUCTION_ACCESS_DISABLE;
  MPU_InitStruct.IsShareable = MPU_ACCESS_NOT_SHAREABLE;
  MPU_InitStruct.IsCacheable = MPU_ACCESS_CACHEABLE;
  MPU_InitStruct.IsBufferable = MPU_ACCESS_BUFFERABLE;

  HAL_MPU_ConfigRegion(&MPU_InitStruct);

  /** Initializes and configures the Region and the memory to be protected
  */
  MPU_InitStruct.Number = MPU_REGION_NUMBER1;
  MPU_InitStruct.BaseAddress = 0x90000000;
  MPU_InitStruct.Size = MPU_REGION_SIZE_512MB;
  MPU_InitStruct.AccessPermission = MPU_REGION_NO_ACCESS;
  MPU_InitStruct.IsCacheable = MPU_ACCESS_NOT_CACHEABLE;
  MPU_InitStruct.IsBufferable = MPU_ACCESS_NOT_BUFFERABLE;

  HAL_MPU_ConfigRegion(&MPU_InitStruct);

  /** Initializes and configures the Region and the memory to be protected
  */
  MPU_InitStruct.Number = MPU_REGION_NUMBER2;
  MPU_InitStruct.Size = MPU_REGION_SIZE_64MB;
  MPU_InitStruct.AccessPermission = MPU_REGION_FULL_ACCESS;
  MPU_InitStruct.IsCacheable = MPU_ACCESS_CACHEABLE;
  MPU_InitStruct.IsBufferable = MPU_ACCESS_BUFFERABLE;

  HAL_MPU_ConfigRegion(&MPU_InitStruct);

  /** Initializes and configures the Region and the memory to be protected
  */
  MPU_InitStruct.Number = MPU_REGION_NUMBER3;
  MPU_InitStruct.BaseAddress = 0xC0000000;
  MPU_InitStruct.Size = MPU_REGION_SIZE_512MB;
  MPU_InitStruct.AccessPermission = MPU_REGION_NO_ACCESS;
  MPU_InitStruct.IsCacheable = MPU_ACCESS_NOT_CACHEABLE;
  MPU_InitStruct.IsBufferable = MPU_ACCESS_NOT_BUFFERABLE;

  HAL_MPU_ConfigRegion(&MPU_InitStruct);

  /** Initializes and configures the Region and the memory to be protected
  */
  MPU_InitStruct.Number = MPU_REGION_NUMBER4;
  MPU_InitStruct.Size = MPU_REGION_SIZE_16MB;
  MPU_InitStruct.AccessPermission = MPU_REGION_FULL_ACCESS;
  MPU_InitStruct.IsCacheable = MPU_ACCESS_CACHEABLE;
  MPU_InitStruct.IsBufferable = MPU_ACCESS_BUFFERABLE;

  HAL_MPU_ConfigRegion(&MPU_InitStruct);
  /* Enables the MPU */
  HAL_MPU_Enable(MPU_PRIVILEGED_DEFAULT);

}

void HAL_TIM_PeriodElapsedCallback(TIM_HandleTypeDef *htim)
{
  if (htim->Instance == TIM6) {
    HAL_IncTick();
  }
}

void HAL_GPIO_EXTI_Callback(uint16_t GPIO_Pin)
{
	if(GPIO_Pin==GPIO_PIN_0)
	{
		if(serialNumber>=5)
			serialNumber=0;

		distance[serialNumber]=Distance;
		updateScreen = 1;

	}
}

void Error_Handler(void)
{
}
